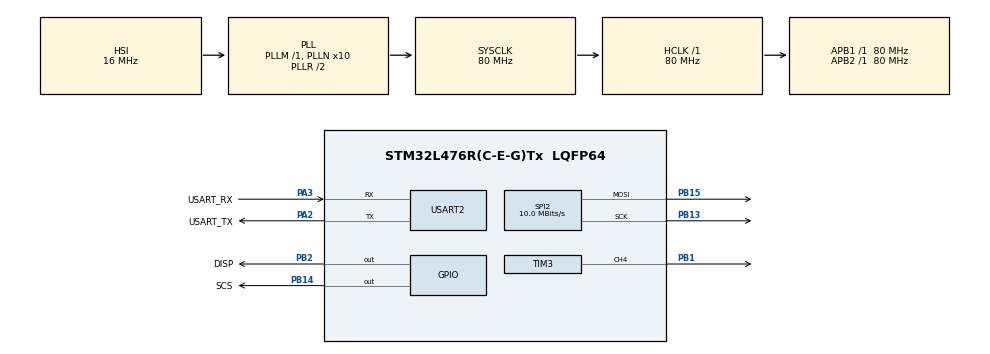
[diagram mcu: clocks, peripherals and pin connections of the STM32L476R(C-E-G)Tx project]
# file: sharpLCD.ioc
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Mcu.Family=STM32L4
Mcu.Name=STM32L476R(C-E-G)Tx
Mcu.Package=LQFP64
NVIC.PriorityGroup=NVIC_PRIORITYGROUP_4
PA13\ (JTMS-SWDIO).Mode=Serial_Wire
PA13\ (JTMS-SWDIO).Signal=SYS_JTMS-SWDIO
PA14\ (JTCK-SWCLK).Mode=Serial_Wire
PA14\ (JTCK-SWCLK).Signal=SYS_JTCK-SWCLK
PA2.GPIO_Label=USART_TX
PA2.GPIO_Mode=GPIO_MODE_AF_PP
PA2.GPIO_ModeDefaultPP=GPIO_MODE_AF_PP
PA2.GPIO_PuPd=GPIO_NOPULL
PA2.GPIO_Speed=GPIO_SPEED_FREQ_VERY_HIGH
PA2.Mode=Asynchronous
PA2.Signal=USART2_TX
PA3.GPIO_Label=USART_RX
PA3.GPIO_Mode=GPIO_MODE_AF_PP
PA3.GPIO_ModeDefaultPP=GPIO_MODE_AF_PP
PA3.GPIO_PuPd=GPIO_NOPULL
PA3.GPIO_Speed=GPIO_SPEED_FREQ_VERY_HIGH
PA3.Mode=Asynchronous
PA3.Signal=USART2_RX
PB1.Signal=S_TIM3_CH4
PB13.GPIO_Mode=GPIO_MODE_AF_PP
PB13.GPIO_PuPd=GPIO_NOPULL
PB13.GPIO_Speed=GPIO_SPEED_FREQ_VERY_HIGH
PB13.Mode=TX_Only_Simplex_Unidirect_Master
PB13.Signal=SPI2_SCK
PB14.GPIO_Label=SCS
PB14.GPIO_Speed=GPIO_SPEED_FREQ_VERY_HIGH
PB14.Signal=GPIO_Output
PB15.GPIO_Mode=GPIO_MODE_AF_PP
PB15.GPIO_PuPd=GPIO_NOPULL
PB15.GPIO_Speed=GPIO_SPEED_FREQ_VERY_HIGH
PB15.Mode=TX_Only_Simplex_Unidirect_Master
PB15.Signal=SPI2_MOSI
PB2.GPIO_Label=DISP
PB2.Signal=GPIO_Output
PB3\ (JTDO-TRACESWO).Signal=SYS_JTDO-SWO
PC15-OSC32_OUT\ (PC15).Signal=RCC_OSC32_OUT
PH0-OSC_IN\ (PH0).Signal=RCC_OSC_IN
PH1-OSC_OUT\ (PH1).Signal=RCC_OSC_OUT
ProjectManager.HeapSize=0x200
ProjectManager.StackSize=0x400
ProjectManager.TargetToolchain=MDK-ARM V5.27
RCC.ADCFreq_Value=96000000
RCC.AHBFreq_Value=80000000
RCC.APB1Freq_Value=80000000
RCC.APB1TimFreq_Value=80000000
RCC.APB2Freq_Value=80000000
RCC.APB2TimFreq_Value=80000000
RCC.CortexFreq_Value=80000000
RCC.HCLKFreq_Value=80000000
RCC.HSE_VALUE=8000000
RCC.HSI_VALUE=16000000
RCC.LSE_VALUE=32768
RCC.MSI_VALUE=4000000
RCC.PLLN=10
RCC.PLLSAI1N=12
RCC.PLLSourceVirtual=RCC_PLLSOURCE_HSI
RCC.PREFETCH_ENABLE=1
RCC.SYSCLKFreq_VALUE=80000000
RCC.SYSCLKSource=RCC_SYSCLKSOURCE_PLLCLK
RCC.USBFreq_Value=96000000
RCC.VCOOutputFreq_Value=160000000
SH.S_TIM3_CH4.0=TIM3_CH4,PWM Generation4 CH4
SPI2.BaudRatePrescaler=SPI_BAUDRATEPRESCALER_8
SPI2.CalculateBaudRate=10.0 MBits/s
SPI2.DataSize=SPI_DATASIZE_8BIT
SPI2.Direction=SPI_DIRECTION_2LINES
SPI2.FirstBit=SPI_FIRSTBIT_LSB
SPI2.Mode=SPI_MODE_MASTER
SPI2.VirtualType=VM_MASTER
TIM3.Channel-PWM\ Generation4\ CH4=TIM_CHANNEL_4
TIM3.Period=199
TIM3.Prescaler=9999
TIM3.Pulse-PWM\ Generation4\ CH4=100
USART2.VirtualMode-Asynchronous=VM_ASYNC
VP_TIM3_VS_ClockSourceINT.Mode=Internal
board=NUCLEO-L476RG

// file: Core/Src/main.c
/* USER CODE BEGIN Header */
/**
  ******************************************************************************
  * @file           : main.c
  * @brief          : Main program body
  ******************************************************************************
  * @attention
  *
  * <h2><center>&copy; Copyright (c) 2020 STMicroelectronics.
  * All rights reserved.</center></h2>
  *
  * This software component is licensed by ST under BSD 3-Clause license,
  * the "License"; You may not use this file except in compliance with the
  * License. You may obtain a copy of the License at:
  *                        opensource.org/licenses/BSD-3-Clause
  *
  ******************************************************************************
  */
/* USER CODE END Header */
#include "main.h"

/* USER CODE BEGIN PTD */
static uint8_t LCD_CMD_CLEAR = 0x56; // 0b01010110
static uint8_t LCD_CMD_UPDATE = 0x93; // 0b10010011
static uint8_t LCD_CMD_NOP = 0x00;
/* USER CODE END PTD */

SPI_HandleTypeDef hspi2;

TIM_HandleTypeDef htim3;

UART_HandleTypeDef huart2;

void SystemClock_Config(void);
static void MX_GPIO_Init(void);
static void MX_TIM3_Init(void);
static void MX_USART2_UART_Init(void);
static void MX_SPI2_Init(void);
/* USER CODE BEGIN PFP */
uint8_t LCD_BUFF[240][50] = {
0 , 0 , 0 , 168 , 170 , 170 , 170 , 170 , 170 , 42 , 34 , 186 , 170 , 170 , 170 , 170 , 254 , 255 , 254 , 255 , 254 , 255 , 238 , 238 , 238 , 174 , 174 , 234 , 238 , 238 , 170 , 34 , 162 , 34 , 2 , 42 , 0 , 0 , 0 , 32 , 0 , 0 , 32 , 0 , 0 , 0 , 0 , 0 , 0 , 0 ,
0 , 0 , 0 , 84 , 85 , 68 , 68 , 68 , 0 , 0 , 0 , 80 , 68 , 0 , 0 , 64 , 213 , 127 , 85 , 125 , 93 , 127 , 85 , 85 , 85 , 85 , 69 , 84 , 85 , 85 , 85 , 5 , 0 , 0 , 0 , 0 , 0 , 0 , 0 , 0 , 0 , 0 , 0 , 0 , 0 , 0 , 0 , 0 , 0 , 0 ,
0 , 0 , 0 , 168 , 170 , 170 , 170 , 170 , 170 , 138 , 0 , 184 , 170 , 170 , 170 , 170 , 251 , 191 , 191 , 187 , 191 , 191 , 171 , 170 , 186 , 171 , 170 , 186 , 187 , 171 , 170 , 138 , 136 , 8 , 0 , 40 , 0 , 0 , 0 , 0 , 0 , 0 , 0 , 0 , 0 , 0 , 0 , 0 , 0 , 0 ,
0 , 0 , 0 , 84 , 17 , 17 , 17 , 0 , 0 , 0 , 0 , 92 , 1 , 0 , 0 , 85 , 213 , 95 , 85 , 93 , 213 , 85 , 85 , 85 , 85 , 85 , 85 , 85 , 85 , 85 , 85 , 1 , 0 , 0 , 0 , 0 , 0 , 0 , 0 , 0 , 0 , 0 , 0 , 0 , 0 , 0 , 0 , 0 , 0 , 0 ,
0 , 0 , 0 , 168 , 170 , 170 , 170 , 170 , 170 , 170 , 162 , 174 , 170 , 170 , 170 , 254 , 238 , 255 , 238 , 254 , 239 , 239 , 238 , 238 , 238 , 238 , 234 , 234 , 250 , 174 , 170 , 170 , 34 , 170 , 2 , 160 , 0 , 0 , 0 , 32 , 0 , 0 , 32 , 0 , 0 , 0 , 0 , 0 , 0 , 0 ,
0 , 0 , 0 , 84 , 85 , 68 , 68 , 68 , 4 , 0 , 0 , 84 , 5 , 0 , 84 , 85 , 213 , 95 , 85 , 93 , 215 , 85 , 85 , 85 , 85 , 85 , 69 , 69 , 80 , 85 , 85 , 5 , 0 , 0 , 0 , 0 , 0 , 0 , 0 , 0 , 0 , 0 , 0 , 0 , 0 , 0 , 0 , 0 , 0 , 0 ,
0 , 0 , 0 , 168 , 170 , 170 , 170 , 170 , 170 , 170 , 136 , 170 , 170 , 170 , 170 , 171 , 250 , 191 , 186 , 190 , 251 , 171 , 170 , 170 , 170 , 171 , 170 , 171 , 186 , 170 , 170 , 170 , 136 , 136 , 10 , 128 , 0 , 0 , 0 , 8 , 0 , 0 , 0 , 0 , 0 , 0 , 0 , 0 , 0 , 0 ,
0 , 0 , 0 , 80 , 17 , 17 , 17 , 0 , 0 , 0 , 0 , 84 , 1 , 16 , 85 , 85 , 213 , 95 , 85 , 85 , 213 , 85 , 85 , 85 , 85 , 85 , 81 , 85 , 85 , 85 , 85 , 17 , 0 , 0 , 0 , 0 , 0 , 0 , 0 , 0 , 0 , 0 , 0 , 0 , 0 , 0 , 0 , 0 , 0 , 0 ,
0 , 0 , 0 , 168 , 170 , 170 , 170 , 170 , 170 , 170 , 170 , 174 , 170 , 170 , 175 , 170 , 238 , 255 , 255 , 255 , 255 , 239 , 238 , 238 , 238 , 238 , 234 , 238 , 238 , 170 , 170 , 170 , 162 , 170 , 42 , 0 , 34 , 0 , 0 , 2 , 0 , 32 , 0 , 0 , 0 , 0 , 0 , 0 , 0 , 0 ,
0 , 0 , 0 , 84 , 85 , 68 , 68 , 68 , 68 , 64 , 68 , 85 , 85 , 85 , 85 , 85 , 245 , 127 , 119 , 247 , 119 , 85 , 85 , 85 , 85 , 85 , 85 , 85 , 84 , 85 , 85 , 85 , 0 , 64 , 4 , 0 , 0 , 0 , 0 , 0 , 0 , 0 , 0 , 0 , 0 , 0 , 0 , 0 , 0 , 0 ,
0 , 0 , 0 , 168 , 170 , 170 , 170 , 170 , 170 , 170 , 170 , 175 , 170 , 186 , 170 , 170 , 250 , 255 , 255 , 255 , 255 , 191 , 170 , 170 , 170 , 170 , 170 , 187 , 186 , 170 , 170 , 170 , 136 , 170 , 170 , 0 , 0 , 8 , 0 , 0 , 0 , 0 , 0 , 0 , 0 , 0 , 0 , 0 , 0 , 0 ,
0 , 0 , 0 , 20 , 17 , 17 , 17 , 1 , 0 , 0 , 81 , 85 , 85 , 85 , 85 , 85 , 245 , 223 , 85 , 215 , 93 , 221 , 85 , 85 , 85 , 85 , 85 , 21 , 85 , 85 , 85 , 21 , 1 , 0 , 17 , 1 , 0 , 0 , 0 , 0 , 0 , 0 , 0 , 0 , 0 , 0 , 0 , 0 , 0 , 0 ,
0 , 0 , 0 , 168 , 170 , 170 , 170 , 170 , 170 , 170 , 234 , 239 , 238 , 170 , 170 , 234 , 251 , 255 , 255 , 239 , 255 , 255 , 239 , 238 , 238 , 238 , 238 , 174 , 238 , 170 , 170 , 170 , 170 , 170 , 170 , 10 , 32 , 42 , 32 , 0 , 160 , 2 , 0 , 0 , 0 , 0 , 0 , 0 , 0 , 0 ,
0 , 0 , 0 , 84 , 85 , 68 , 68 , 68 , 68 , 84 , 85 , 85 , 85 , 85 , 85 , 85 , 247 , 127 , 119 , 215 , 117 , 119 , 85 , 85 , 85 , 85 , 85 , 69 , 85 , 85 , 85 , 85 , 5 , 68 , 85 , 5 , 0 , 0 , 0 , 0 , 0 , 0 , 0 , 0 , 0 , 0 , 0 , 0 , 0 , 0 ,
0 , 0 , 0 , 168 , 170 , 170 , 170 , 170 , 170 , 170 , 250 , 187 , 170 , 170 , 170 , 187 , 251 , 255 , 255 , 255 , 255 , 255 , 251 , 171 , 170 , 170 , 170 , 170 , 187 , 170 , 170 , 170 , 138 , 170 , 170 , 10 , 0 , 136 , 8 , 0 , 128 , 0 , 0 , 0 , 0 , 0 , 0 , 0 , 0 , 0 ,
0 , 0 , 0 , 84 , 17 , 17 , 17 , 1 , 16 , 85 , 85 , 85 , 85 , 85 , 81 , 125 , 221 , 93 , 85 , 215 , 85 , 85 , 213 , 85 , 85 , 85 , 85 , 17 , 85 , 85 , 85 , 85 , 17 , 16 , 17 , 1 , 0 , 0 , 0 , 0 , 0 , 0 , 0 , 0 , 0 , 0 , 0 , 0 , 0 , 0 ,
0 , 0 , 0 , 168 , 170 , 170 , 170 , 170 , 170 , 238 , 239 , 238 , 174 , 170 , 234 , 255 , 255 , 255 , 255 , 255 , 255 , 254 , 255 , 239 , 238 , 238 , 238 , 170 , 238 , 170 , 170 , 170 , 42 , 170 , 170 , 42 , 0 , 2 , 42 , 2 , 40 , 0 , 32 , 0 , 0 , 0 , 0 , 0 , 0 , 0 ,
0 , 0 , 0 , 84 , 85 , 68 , 68 , 68 , 84 , 85 , 85 , 85 , 85 , 85 , 117 , 255 , 255 , 119 , 119 , 87 , 117 , 87 , 85 , 87 , 85 , 85 , 85 , 5 , 84 , 85 , 85 , 85 , 85 , 84 , 85 , 5 , 0 , 0 , 0 , 0 , 0 , 0 , 0 , 0 , 0 , 0 , 0 , 0 , 0 , 0 ,
0 , 0 , 0 , 168 , 170 , 170 , 170 , 170 , 170 , 187 , 187 , 171 , 170 , 170 , 255 , 255 , 255 , 255 , 255 , 191 , 255 , 187 , 187 , 191 , 171 , 170 , 186 , 138 , 186 , 170 , 170 , 170 , 170 , 170 , 170 , 42 , 0 , 0 , 8 , 128 , 10 , 0 , 0 , 0 , 0 , 0 , 0 , 0 , 0 , 0 ,
0 , 0 , 0 , 84 , 21 , 17 , 17 , 16 , 85 , 85 , 85 , 85 , 85 , 213 , 223 , 255 , 221 , 93 , 85 , 213 , 85 , 85 , 85 , 85 , 85 , 85 , 85 , 69 , 85 , 85 , 85 , 85 , 21 , 17 , 17 , 17 , 0 , 0 , 0 , 0 , 0 , 0 , 0 , 0 , 0 , 0 , 0 , 0 , 0 , 0 ,
0 , 0 , 0 , 168 , 170 , 170 , 170 , 234 , 254 , 238 , 255 , 239 , 255 , 255 , 239 , 255 , 255 , 255 , 255 , 255 , 255 , 239 , 238 , 238 , 239 , 238 , 238 , 174 , 239 , 170 , 170 , 174 , 170 , 170 , 170 , 170 , 40 , 32 , 170 , 170 , 34 , 0 , 32 , 32 , 32 , 0 , 0 , 0 , 0 , 0 ,
0 , 0 , 0 , 84 , 85 , 69 , 68 , 85 , 85 , 85 , 85 , 117 , 119 , 87 , 117 , 85 , 127 , 127 , 119 , 87 , 117 , 87 , 85 , 85 , 87 , 85 , 85 , 85 , 85 , 85 , 85 , 85 , 85 , 85 , 85 , 69 , 80 , 0 , 68 , 68 , 0 , 0 , 0 , 0 , 0 , 0 , 0 , 0 , 0 , 0 ,
0 , 0 , 0 , 168 , 170 , 170 , 170 , 186 , 187 , 170 , 170 , 170 , 170 , 170 , 186 , 170 , 255 , 255 , 255 , 191 , 255 , 191 , 187 , 187 , 191 , 187 , 171 , 187 , 171 , 170 , 170 , 170 , 170 , 170 , 170 , 170 , 186 , 138 , 170 , 170 , 170 , 8 , 0 , 0 , 0 , 0 , 0 , 0 , 0 , 0 ,
0 , 0 , 0 , 84 , 85 , 17 , 85 , 85 , 85 , 85 , 21 , 17 , 17 , 85 , 85 , 213 , 223 , 93 , 85 , 85 , 85 , 85 , 85 , 85 , 85 , 85 , 85 , 85 , 85 , 85 , 85 , 85 , 21 , 17 , 17 , 17 , 81 , 1 , 0 , 1 , 0 , 0 , 0 , 0 , 0 , 0 , 0 , 0 , 0 , 0 ,
0 , 0 , 0 , 236 , 170 , 234 , 254 , 239 , 238 , 170 , 170 , 170 , 170 , 170 , 170 , 238 , 255 , 255 , 255 , 239 , 255 , 239 , 238 , 238 , 254 , 238 , 238 , 238 , 174 , 170 , 170 , 170 , 170 , 170 , 170 , 170 , 234 , 170 , 170 , 170 , 170 , 42 , 42 , 162 , 2 , 34 , 0 , 0 , 0 , 0 ,
0 , 0 , 0 , 84 , 85 , 85 , 245 , 85 , 85 , 85 , 85 , 85 , 85 , 85 , 85 , 213 , 127 , 127 , 127 , 95 , 117 , 87 , 85 , 85 , 85 , 85 , 85 , 85 , 85 , 85 , 85 , 85 , 85 , 85 , 85 , 69 , 84 , 69 , 4 , 0 , 0 , 0 , 0 , 0 , 4 , 0 , 0 , 0 , 0 , 0 ,
0 , 0 , 0 , 184 , 187 , 251 , 255 , 187 , 171 , 170 , 170 , 170 , 170 , 170 , 170 , 234 , 255 , 255 , 255 , 255 , 255 , 191 , 170 , 187 , 187 , 187 , 171 , 187 , 187 , 170 , 170 , 170 , 170 , 170 , 170 , 170 , 170 , 170 , 170 , 138 , 136 , 170 , 128 , 128 , 136 , 0 , 0 , 0 , 0 , 0 ,
0 , 0 , 0 , 84 , 85 , 21 , 212 , 85 , 85 , 21 , 17 , 17 , 81 , 17 , 17 , 213 , 221 , 93 , 85 , 221 , 221 , 85 , 85 , 85 , 85 , 85 , 85 , 85 , 85 , 85 , 85 , 85 , 85 , 17 , 17 , 17 , 81 , 1 , 0 , 0 , 0 , 0 , 0 , 0 , 0 , 0 , 0 , 0 , 0 , 0 ,
0 , 0 , 0 , 252 , 238 , 42 , 254 , 239 , 174 , 170 , 170 , 170 , 170 , 170 , 170 , 234 , 255 , 255 , 255 , 255 , 255 , 255 , 238 , 238 , 254 , 254 , 238 , 239 , 238 , 170 , 170 , 170 , 170 , 170 , 170 , 170 , 234 , 170 , 170 , 42 , 0 , 34 , 42 , 34 , 32 , 0 , 0 , 0 , 0 , 0 ,
0 , 0 , 0 , 124 , 85 , 21 , 116 , 85 , 85 , 85 , 85 , 85 , 85 , 85 , 85 , 213 , 93 , 127 , 119 , 119 , 95 , 119 , 85 , 85 , 85 , 85 , 85 , 85 , 85 , 85 , 85 , 85 , 85 , 85 , 85 , 84 , 85 , 69 , 0 , 0 , 0 , 0 , 0 , 0 , 0 , 0 , 0 , 0 , 0 , 0 ,
0 , 0 , 0 , 188 , 170 , 43 , 254 , 187 , 171 , 170 , 170 , 170 , 170 , 170 , 170 , 186 , 255 , 255 , 255 , 255 , 255 , 255 , 187 , 170 , 186 , 187 , 187 , 187 , 187 , 171 , 170 , 170 , 170 , 170 , 170 , 170 , 186 , 170 , 168 , 8 , 0 , 0 , 0 , 0 , 128 , 0 , 0 , 0 , 0 , 0 ,
0 , 0 , 0 , 92 , 85 , 21 , 212 , 21 , 85 , 17 , 17 , 17 , 21 , 17 , 17 , 209 , 221 , 221 , 85 , 117 , 221 , 85 , 85 , 85 , 80 , 85 , 85 , 85 , 85 , 85 , 85 , 85 , 85 , 21 , 17 , 81 , 85 , 17 , 0 , 0 , 0 , 0 , 0 , 0 , 0 , 0 , 0 , 0 , 0 , 0 ,
0 , 0 , 0 , 252 , 239 , 170 , 254 , 175 , 174 , 170 , 170 , 170 , 170 , 170 , 170 , 234 , 255 , 255 , 255 , 255 , 255 , 255 , 255 , 47 , 234 , 238 , 239 , 239 , 238 , 238 , 170 , 170 , 170 , 170 , 170 , 234 , 238 , 170 , 170 , 10 , 0 , 0 , 32 , 0 , 0 , 2 , 0 , 0 , 0 , 0 ,
0 , 0 , 0 , 84 , 71 , 85 , 116 , 85 , 85 , 85 , 85 , 85 , 85 , 85 , 85 , 212 , 119 , 247 , 119 , 247 , 255 , 119 , 119 , 7 , 80 , 85 , 85 , 85 , 85 , 85 , 85 , 85 , 85 , 85 , 85 , 68 , 85 , 69 , 4 , 4 , 0 , 0 , 0 , 0 , 0 , 0 , 0 , 0 , 0 , 0 ,
0 , 0 , 0 , 236 , 175 , 171 , 248 , 187 , 170 , 170 , 170 , 170 , 170 , 170 , 234 , 251 , 191 , 255 , 255 , 255 , 255 , 255 , 255 , 175 , 170 , 186 , 171 , 187 , 187 , 187 , 171 , 170 , 170 , 170 , 170 , 170 , 170 , 170 , 138 , 10 , 0 , 0 , 128 , 0 , 0 , 0 , 0 , 0 , 0 , 0 ,
0 , 0 , 0 , 212 , 85 , 21 , 84 , 85 , 21 , 17 , 17 , 17 , 17 , 17 , 1 , 209 , 93 , 221 , 95 , 213 , 93 , 93 , 85 , 85 , 4 , 85 , 85 , 85 , 85 , 85 , 85 , 85 , 85 , 21 , 17 , 81 , 85 , 17 , 5 , 0 , 0 , 0 , 0 , 0 , 0 , 0 , 0 , 0 , 0 , 0 ,
0 , 0 , 0 , 252 , 63 , 174 , 250 , 191 , 170 , 170 , 170 , 170 , 170 , 170 , 170 , 238 , 255 , 255 , 255 , 255 , 255 , 255 , 255 , 255 , 170 , 238 , 254 , 238 , 238 , 238 , 238 , 170 , 170 , 170 , 170 , 234 , 238 , 170 , 42 , 34 , 0 , 0 , 0 , 2 , 0 , 32 , 0 , 0 , 0 , 0 ,
0 , 0 , 0 , 244 , 23 , 84 , 116 , 85 , 85 , 85 , 85 , 85 , 85 , 69 , 68 , 92 , 119 , 255 , 127 , 117 , 247 , 119 , 87 , 85 , 69 , 85 , 85 , 85 , 85 , 85 , 85 , 85 , 85 , 85 , 85 , 85 , 85 , 85 , 20 , 0 , 0 , 0 , 0 , 0 , 0 , 0 , 0 , 0 , 0 , 0 ,
0 , 0 , 0 , 252 , 63 , 168 , 250 , 187 , 170 , 170 , 170 , 170 , 170 , 170 , 170 , 250 , 255 , 255 , 255 , 251 , 255 , 255 , 255 , 251 , 171 , 170 , 187 , 171 , 170 , 187 , 171 , 170 , 170 , 170 , 170 , 170 , 187 , 171 , 42 , 0 , 0 , 0 , 0 , 8 , 0 , 0 , 0 , 0 , 0 , 0 ,
0 , 0 , 0 , 212 , 29 , 16 , 81 , 85 , 21 , 17 , 17 , 17 , 17 , 21 , 17 , 80 , 213 , 221 , 125 , 85 , 223 , 93 , 85 , 85 , 21 , 81 , 85 , 21 , 85 , 85 , 85 , 17 , 85 , 85 , 17 , 81 , 85 , 85 , 17 , 0 , 0 , 0 , 0 , 0 , 0 , 0 , 0 , 0 , 0 , 0 ,
0 , 0 , 0 , 252 , 63 , 184 , 250 , 239 , 170 , 170 , 170 , 170 , 170 , 170 , 170 , 234 , 255 , 255 , 255 , 239 , 255 , 255 , 254 , 255 , 238 , 234 , 238 , 238 , 234 , 238 , 238 , 170 , 170 , 170 , 170 , 234 , 238 , 238 , 170 , 2 , 0 , 0 , 0 , 32 , 0 , 0 , 0 , 0 , 0 , 0 ,
0 , 0 , 0 , 84 , 95 , 80 , 116 , 85 , 85 , 85 , 85 , 85 , 85 , 69 , 68 , 68 , 127 , 247 , 255 , 87 , 253 , 127 , 85 , 85 , 85 , 85 , 85 , 85 , 85 , 85 , 85 , 85 , 85 , 85 , 85 , 85 , 85 , 85 , 69 , 0 , 0 , 0 , 0 , 0 , 0 , 0 , 0 , 0 , 0 , 0 ,
0 , 0 , 0 , 184 , 63 , 160 , 186 , 187 , 171 , 170 , 170 , 170 , 170 , 170 , 170 , 234 , 255 , 255 , 255 , 191 , 251 , 255 , 255 , 187 , 187 , 171 , 186 , 255 , 171 , 170 , 186 , 170 , 170 , 170 , 170 , 186 , 171 , 187 , 170 , 10 , 0 , 0 , 0 , 128 , 0 , 0 , 0 , 0 , 0 , 0 ,
0 , 0 , 0 , 84 , 21 , 64 , 85 , 85 , 85 , 17 , 17 , 17 , 17 , 17 , 1 , 192 , 221 , 213 , 221 , 95 , 245 , 255 , 85 , 85 , 85 , 21 , 85 , 93 , 85 , 85 , 85 , 85 , 17 , 85 , 17 , 81 , 85 , 85 , 17 , 1 , 0 , 0 , 0 , 0 , 0 , 0 , 0 , 0 , 0 , 0 ,
0 , 0 , 0 , 252 , 42 , 224 , 250 , 190 , 171 , 170 , 170 , 170 , 170 , 170 , 170 , 170 , 255 , 255 , 255 , 255 , 255 , 255 , 255 , 255 , 255 , 191 , 234 , 254 , 175 , 238 , 238 , 238 , 170 , 170 , 170 , 234 , 238 , 238 , 170 , 42 , 2 , 0 , 0 , 0 , 2 , 0 , 0 , 0 , 0 , 0 ,
0 , 0 , 0 , 84 , 85 , 64 , 85 , 85 , 85 , 85 , 85 , 85 , 85 , 69 , 68 , 64 , 119 , 119 , 247 , 127 , 245 , 255 , 87 , 85 , 85 , 85 , 84 , 85 , 85 , 85 , 85 , 85 , 85 , 85 , 85 , 85 , 85 , 85 , 69 , 1 , 0 , 0 , 0 , 0 , 0 , 0 , 0 , 0 , 0 , 0 ,
0 , 0 , 0 , 168 , 42 , 128 , 186 , 251 , 171 , 170 , 170 , 170 , 170 , 170 , 170 , 170 , 254 , 255 , 255 , 255 , 255 , 255 , 239 , 187 , 187 , 187 , 170 , 254 , 187 , 170 , 170 , 170 , 171 , 170 , 170 , 186 , 171 , 186 , 171 , 2 , 0 , 0 , 0 , 0 , 0 , 0 , 0 , 0 , 0 , 0 ,
0 , 0 , 0 , 84 , 21 , 0 , 85 , 85 , 21 , 17 , 17 , 17 , 21 , 17 , 1 , 0 , 221 , 93 , 221 , 253 , 215 , 221 , 95 , 85 , 85 , 85 , 81 , 85 , 21 , 85 , 85 , 85 , 21 , 81 , 21 , 85 , 85 , 85 , 21 , 1 , 0 , 0 , 0 , 0 , 0 , 0 , 0 , 0 , 0 , 0 ,
0 , 0 , 0 , 172 , 42 , 130 , 254 , 238 , 175 , 170 , 170 , 170 , 170 , 170 , 170 , 170 , 254 , 255 , 255 , 255 , 255 , 255 , 255 , 255 , 255 , 255 , 170 , 254 , 191 , 238 , 238 , 238 , 174 , 170 , 170 , 238 , 238 , 238 , 174 , 42 , 2 , 0 , 0 , 0 , 34 , 0 , 0 , 0 , 0 , 0 ,
0 , 0 , 0 , 84 , 85 , 0 , 85 , 85 , 85 , 85 , 85 , 85 , 85 , 69 , 68 , 64 , 244 , 247 , 119 , 255 , 127 , 255 , 127 , 85 , 85 , 85 , 69 , 85 , 85 , 85 , 85 , 85 , 85 , 85 , 85 , 85 , 85 , 85 , 85 , 68 , 0 , 0 , 0 , 0 , 0 , 0 , 0 , 0 , 0 , 0 ,
0 , 0 , 0 , 168 , 42 , 128 , 191 , 187 , 171 , 170 , 170 , 170 , 170 , 170 , 170 , 170 , 250 , 255 , 255 , 255 , 255 , 255 , 255 , 190 , 187 , 187 , 171 , 254 , 187 , 170 , 171 , 170 , 186 , 171 , 170 , 186 , 187 , 171 , 171 , 170 , 0 , 0 , 0 , 0 , 0 , 0 , 0 , 0 , 0 , 0 ,
0 , 0 , 0 , 84 , 21 , 0 , 93 , 85 , 85 , 17 , 81 , 21 , 17 , 21 , 1 , 0 , 208 , 223 , 221 , 221 , 253 , 221 , 221 , 85 , 85 , 85 , 21 , 85 , 85 , 84 , 85 , 85 , 85 , 21 , 17 , 81 , 85 , 85 , 21 , 1 , 1 , 0 , 0 , 0 , 0 , 0 , 0 , 0 , 0 , 0 ,
0 , 0 , 0 , 172 , 42 , 160 , 255 , 238 , 175 , 170 , 234 , 170 , 170 , 170 , 170 , 170 , 234 , 255 , 255 , 255 , 255 , 255 , 255 , 255 , 255 , 255 , 175 , 254 , 255 , 234 , 238 , 238 , 238 , 174 , 170 , 234 , 238 , 238 , 174 , 170 , 2 , 0 , 0 , 0 , 0 , 0 , 0 , 0 , 0 , 0 ,
0 , 0 , 0 , 84 , 85 , 0 , 95 , 85 , 85 , 85 , 69 , 85 , 85 , 69 , 69 , 64 , 68 , 255 , 255 , 255 , 255 , 255 , 119 , 87 , 85 , 85 , 69 , 117 , 85 , 65 , 85 , 85 , 85 , 85 , 85 , 85 , 85 , 85 , 85 , 20 , 4 , 0 , 0 , 0 , 0 , 0 , 0 , 0 , 0 , 0 ,
0 , 0 , 0 , 168 , 42 , 0 , 254 , 171 , 171 , 170 , 170 , 170 , 170 , 170 , 170 , 170 , 170 , 254 , 255 , 255 , 255 , 255 , 255 , 239 , 187 , 187 , 171 , 250 , 191 , 171 , 187 , 171 , 170 , 186 , 170 , 186 , 187 , 187 , 187 , 42 , 10 , 0 , 0 , 0 , 0 , 0 , 0 , 0 , 0 , 0 ,
0 , 0 , 0 , 80 , 21 , 0 , 92 , 85 , 85 , 21 , 17 , 17 , 17 , 17 , 1 , 1 , 1 , 252 , 253 , 221 , 221 , 221 , 221 , 85 , 85 , 85 , 21 , 81 , 85 , 5 , 85 , 85 , 85 , 85 , 17 , 81 , 85 , 85 , 85 , 17 , 0 , 0 , 0 , 0 , 0 , 0 , 0 , 0 , 0 , 0 ,
0 , 0 , 0 , 168 , 42 , 32 , 254 , 174 , 175 , 170 , 170 , 170 , 170 , 170 , 170 , 170 , 170 , 250 , 255 , 255 , 255 , 255 , 255 , 191 , 255 , 255 , 175 , 250 , 239 , 42 , 234 , 238 , 238 , 238 , 170 , 234 , 238 , 238 , 238 , 170 , 168 , 2 , 0 , 0 , 0 , 0 , 0 , 0 , 0 , 0 ,
0 , 0 , 0 , 84 , 85 , 0 , 116 , 85 , 85 , 85 , 85 , 84 , 85 , 85 , 69 , 64 , 68 , 212 , 255 , 247 , 255 , 255 , 119 , 87 , 87 , 85 , 85 , 84 , 85 , 85 , 84 , 85 , 85 , 85 , 85 , 85 , 85 , 85 , 85 , 69 , 64 , 0 , 0 , 0 , 0 , 0 , 0 , 0 , 0 , 0 ,
0 , 0 , 0 , 168 , 170 , 0 , 248 , 139 , 187 , 170 , 170 , 170 , 170 , 170 , 170 , 138 , 170 , 170 , 255 , 255 , 255 , 255 , 255 , 191 , 190 , 187 , 171 , 250 , 171 , 170 , 170 , 186 , 170 , 170 , 170 , 186 , 187 , 187 , 187 , 170 , 128 , 10 , 0 , 0 , 0 , 0 , 0 , 0 , 0 , 0 ,
0 , 0 , 0 , 80 , 85 , 0 , 80 , 21 , 85 , 21 , 17 , 17 , 17 , 17 , 17 , 17 , 0 , 80 , 253 , 223 , 221 , 221 , 93 , 93 , 85 , 85 , 21 , 81 , 85 , 21 , 1 , 80 , 85 , 85 , 85 , 85 , 85 , 85 , 85 , 1 , 0 , 0 , 0 , 0 , 0 , 0 , 0 , 0 , 0 , 0 ,
0 , 0 , 0 , 168 , 170 , 34 , 224 , 175 , 250 , 170 , 170 , 170 , 170 , 170 , 170 , 170 , 170 , 234 , 254 , 255 , 255 , 255 , 255 , 255 , 251 , 255 , 175 , 234 , 170 , 170 , 170 , 234 , 238 , 238 , 170 , 254 , 238 , 238 , 238 , 170 , 42 , 162 , 2 , 0 , 0 , 0 , 0 , 0 , 0 , 0 ,
0 , 0 , 0 , 84 , 85 , 0 , 96 , 85 , 85 , 85 , 85 , 69 , 85 , 85 , 85 , 85 , 85 , 68 , 245 , 255 , 255 , 127 , 127 , 119 , 119 , 85 , 85 , 84 , 85 , 85 , 69 , 65 , 85 , 85 , 85 , 85 , 85 , 85 , 85 , 69 , 0 , 0 , 4 , 0 , 0 , 0 , 0 , 0 , 0 , 0 ,
0 , 0 , 0 , 168 , 170 , 0 , 224 , 171 , 186 , 170 , 170 , 170 , 170 , 170 , 170 , 170 , 170 , 170 , 186 , 255 , 255 , 255 , 255 , 251 , 239 , 187 , 171 , 170 , 170 , 170 , 170 , 170 , 170 , 170 , 170 , 250 , 187 , 187 , 187 , 170 , 0 , 128 , 10 , 0 , 0 , 0 , 0 , 0 , 0 , 0 ,
0 , 0 , 0 , 80 , 21 , 0 , 64 , 85 , 85 , 85 , 21 , 17 , 81 , 21 , 81 , 85 , 85 , 85 , 85 , 125 , 255 , 221 , 221 , 213 , 93 , 85 , 21 , 81 , 85 , 21 , 1 , 16 , 85 , 85 , 85 , 85 , 85 , 85 , 85 , 21 , 0 , 0 , 0 , 0 , 0 , 0 , 0 , 0 , 0 , 0 ,
0 , 0 , 0 , 168 , 42 , 34 , 226 , 239 , 238 , 170 , 170 , 170 , 170 , 170 , 170 , 170 , 238 , 238 , 238 , 255 , 254 , 255 , 255 , 239 , 255 , 255 , 191 , 170 , 170 , 170 , 42 , 186 , 238 , 234 , 238 , 254 , 255 , 238 , 238 , 174 , 42 , 32 , 42 , 32 , 2 , 32 , 0 , 0 , 0 , 0 ,
0 , 0 , 0 , 84 , 21 , 0 , 0 , 85 , 85 , 85 , 85 , 85 , 85 , 85 , 85 , 85 , 85 , 85 , 85 , 119 , 253 , 127 , 119 , 87 , 119 , 85 , 85 , 68 , 85 , 85 , 4 , 84 , 84 , 85 , 85 , 85 , 85 , 85 , 85 , 85 , 0 , 0 , 0 , 0 , 0 , 0 , 0 , 0 , 0 , 0 ,
0 , 0 , 0 , 168 , 170 , 8 , 128 , 171 , 186 , 171 , 170 , 170 , 170 , 170 , 170 , 170 , 170 , 187 , 191 , 255 , 255 , 255 , 255 , 255 , 255 , 187 , 187 , 170 , 170 , 170 , 10 , 186 , 168 , 170 , 170 , 250 , 191 , 187 , 170 , 170 , 8 , 128 , 128 , 0 , 0 , 0 , 0 , 0 , 0 , 0 ,
0 , 0 , 0 , 80 , 21 , 0 , 0 , 85 , 85 , 85 , 85 , 21 , 85 , 21 , 85 , 85 , 85 , 85 , 213 , 93 , 85 , 221 , 85 , 221 , 95 , 85 , 85 , 65 , 21 , 17 , 0 , 85 , 81 , 85 , 85 , 85 , 85 , 85 , 85 , 21 , 1 , 0 , 0 , 0 , 0 , 0 , 0 , 0 , 0 , 0 ,
0 , 0 , 0 , 168 , 170 , 10 , 2 , 174 , 254 , 175 , 170 , 170 , 238 , 238 , 238 , 238 , 255 , 255 , 255 , 255 , 175 , 254 , 174 , 170 , 254 , 255 , 239 , 234 , 175 , 170 , 162 , 255 , 170 , 174 , 234 , 254 , 255 , 239 , 238 , 174 , 34 , 32 , 34 , 2 , 2 , 0 , 0 , 0 , 0 , 0 ,
0 , 0 , 0 , 84 , 85 , 0 , 0 , 84 , 85 , 85 , 85 , 85 , 85 , 85 , 85 , 85 , 85 , 85 , 85 , 85 , 4 , 80 , 0 , 0 , 64 , 119 , 85 , 69 , 85 , 0 , 64 , 85 , 5 , 85 , 85 , 85 , 85 , 85 , 85 , 85 , 0 , 0 , 0 , 0 , 0 , 0 , 0 , 0 , 0 , 0 ,
0 , 0 , 0 , 168 , 170 , 10 , 0 , 188 , 186 , 175 , 170 , 170 , 170 , 187 , 187 , 187 , 171 , 170 , 170 , 170 , 10 , 56 , 0 , 0 , 136 , 254 , 187 , 170 , 170 , 138 , 234 , 187 , 59 , 170 , 170 , 250 , 255 , 187 , 187 , 170 , 2 , 0 , 0 , 8 , 0 , 0 , 0 , 0 , 0 , 0 ,
0 , 0 , 0 , 80 , 21 , 0 , 0 , 80 , 85 , 85 , 85 , 85 , 85 , 85 , 85 , 21 , 0 , 16 , 17 , 1 , 4 , 16 , 0 , 0 , 0 , 208 , 85 , 1 , 0 , 0 , 85 , 85 , 85 , 64 , 85 , 85 , 85 , 85 , 85 , 21 , 0 , 0 , 0 , 0 , 0 , 0 , 0 , 0 , 0 , 0 ,
0 , 0 , 0 , 168 , 170 , 42 , 34 , 248 , 254 , 254 , 234 , 238 , 238 , 254 , 175 , 170 , 170 , 170 , 170 , 170 , 170 , 42 , 34 , 34 , 2 , 226 , 255 , 42 , 168 , 170 , 234 , 239 , 254 , 163 , 254 , 250 , 255 , 255 , 238 , 174 , 34 , 32 , 34 , 34 , 0 , 0 , 0 , 0 , 0 , 0 ,
0 , 0 , 0 , 84 , 85 , 1 , 0 , 112 , 85 , 85 , 85 , 85 , 85 , 85 , 69 , 68 , 68 , 68 , 68 , 4 , 4 , 20 , 0 , 0 , 0 , 64 , 85 , 69 , 64 , 85 , 85 , 85 , 85 , 21 , 84 , 85 , 85 , 85 , 85 , 85 , 0 , 0 , 0 , 0 , 0 , 0 , 0 , 0 , 0 , 0 ,
0 , 0 , 0 , 168 , 170 , 10 , 0 , 224 , 235 , 187 , 170 , 170 , 187 , 171 , 170 , 170 , 170 , 170 , 170 , 170 , 138 , 26 , 0 , 0 , 0 , 128 , 239 , 171 , 168 , 170 , 234 , 187 , 187 , 187 , 186 , 187 , 251 , 191 , 187 , 171 , 2 , 0 , 0 , 128 , 0 , 0 , 0 , 0 , 0 , 0 ,
0 , 0 , 0 , 80 , 85 , 1 , 0 , 64 , 85 , 85 , 85 , 85 , 85 , 17 , 17 , 17 , 17 , 17 , 17 , 0 , 20 , 20 , 0 , 0 , 0 , 128 , 21 , 5 , 0 , 17 , 81 , 85 , 85 , 85 , 85 , 85 , 85 , 85 , 85 , 21 , 0 , 0 , 0 , 0 , 0 , 0 , 0 , 0 , 0 , 0 ,
0 , 0 , 0 , 168 , 170 , 42 , 34 , 224 , 239 , 239 , 238 , 238 , 175 , 170 , 170 , 170 , 170 , 170 , 170 , 170 , 174 , 62 , 34 , 34 , 0 , 128 , 255 , 174 , 160 , 170 , 234 , 239 , 254 , 238 , 238 , 255 , 255 , 255 , 255 , 175 , 34 , 32 , 32 , 2 , 2 , 0 , 0 , 0 , 0 , 0 ,
0 , 0 , 0 , 84 , 85 , 1 , 0 , 64 , 85 , 87 , 85 , 85 , 85 , 85 , 85 , 68 , 68 , 68 , 68 , 68 , 84 , 21 , 0 , 0 , 0 , 0 , 127 , 21 , 0 , 84 , 84 , 85 , 85 , 85 , 85 , 85 , 85 , 85 , 85 , 85 , 4 , 0 , 0 , 0 , 0 , 0 , 0 , 0 , 0 , 0 ,
0 , 0 , 0 , 168 , 170 , 10 , 0 , 128 , 255 , 191 , 187 , 187 , 170 , 170 , 170 , 170 , 170 , 170 , 170 , 170 , 170 , 186 , 0 , 0 , 0 , 0 , 255 , 191 , 130 , 170 , 170 , 187 , 187 , 187 , 187 , 186 , 255 , 255 , 187 , 171 , 10 , 0 , 8 , 0 , 0 , 0 , 0 , 0 , 0 , 0 ,
0 , 0 , 0 , 80 , 85 , 1 , 0 , 0 , 85 , 85 , 85 , 85 , 21 , 85 , 17 , 17 , 17 , 17 , 17 , 17 , 20 , 81 , 0 , 0 , 0 , 0 , 223 , 93 , 1 , 16 , 81 , 85 , 21 , 16 , 80 , 85 , 85 , 85 , 85 , 21 , 0 , 0 , 0 , 0 , 0 , 0 , 0 , 0 , 0 , 0 ,
0 , 0 , 0 , 168 , 170 , 10 , 34 , 32 , 254 , 255 , 238 , 238 , 170 , 170 , 170 , 170 , 170 , 170 , 170 , 170 , 174 , 234 , 34 , 34 , 2 , 0 , 254 , 255 , 171 , 170 , 234 , 175 , 170 , 170 , 174 , 238 , 255 , 255 , 255 , 174 , 42 , 2 , 0 , 0 , 0 , 0 , 0 , 0 , 0 , 0 ,
0 , 0 , 0 , 84 , 85 , 5 , 0 , 0 , 84 , 117 , 85 , 85 , 85 , 69 , 85 , 69 , 69 , 68 , 69 , 68 , 68 , 84 , 1 , 0 , 0 , 0 , 254 , 119 , 95 , 84 , 85 , 87 , 85 , 85 , 85 , 117 , 85 , 85 , 85 , 85 , 4 , 0 , 0 , 0 , 0 , 0 , 0 , 0 , 0 , 0 ,
0 , 0 , 0 , 168 , 170 , 10 , 0 , 0 , 248 , 251 , 187 , 171 , 170 , 170 , 171 , 170 , 170 , 170 , 170 , 170 , 170 , 170 , 139 , 8 , 0 , 0 , 254 , 255 , 255 , 171 , 170 , 191 , 187 , 187 , 187 , 234 , 255 , 255 , 187 , 171 , 10 , 0 , 0 , 0 , 0 , 0 , 0 , 0 , 0 , 0 ,
0 , 0 , 0 , 80 , 85 , 1 , 0 , 0 , 64 , 85 , 85 , 85 , 85 , 21 , 17 , 17 , 17 , 17 , 17 , 17 , 21 , 17 , 5 , 0 , 0 , 0 , 252 , 95 , 213 , 21 , 85 , 85 , 85 , 85 , 85 , 209 , 85 , 85 , 85 , 21 , 0 , 0 , 0 , 0 , 0 , 0 , 0 , 0 , 0 , 0 ,
0 , 0 , 0 , 168 , 170 , 42 , 34 , 32 , 162 , 254 , 255 , 175 , 170 , 170 , 170 , 170 , 170 , 170 , 170 , 170 , 174 , 170 , 190 , 42 , 34 , 2 , 254 , 255 , 255 , 175 , 239 , 239 , 238 , 238 , 238 , 254 , 251 , 255 , 255 , 175 , 42 , 34 , 34 , 0 , 0 , 0 , 0 , 0 , 0 , 0 ,
0 , 0 , 0 , 84 , 85 , 5 , 0 , 0 , 0 , 84 , 85 , 85 , 85 , 85 , 84 , 85 , 85 , 85 , 85 , 85 , 85 , 85 , 117 , 0 , 0 , 0 , 255 , 127 , 119 , 85 , 87 , 87 , 85 , 85 , 85 , 21 , 71 , 85 , 85 , 85 , 0 , 0 , 0 , 0 , 0 , 0 , 0 , 0 , 0 , 0 ,
0 , 0 , 0 , 168 , 170 , 10 , 0 , 0 , 128 , 168 , 191 , 171 , 170 , 170 , 170 , 170 , 170 , 170 , 170 , 170 , 170 , 170 , 170 , 139 , 136 , 136 , 255 , 255 , 255 , 255 , 175 , 191 , 187 , 186 , 170 , 143 , 170 , 255 , 191 , 187 , 10 , 0 , 0 , 0 , 0 , 0 , 0 , 0 , 0 , 0 ,
0 , 0 , 0 , 80 , 85 , 5 , 0 , 0 , 0 , 0 , 93 , 85 , 85 , 85 , 17 , 17 , 17 , 17 , 17 , 17 , 21 , 17 , 81 , 85 , 0 , 0 , 255 , 223 , 223 , 221 , 95 , 85 , 85 , 85 , 85 , 5 , 0 , 85 , 85 , 85 , 1 , 0 , 0 , 0 , 0 , 0 , 0 , 0 , 0 , 0 ,
0 , 0 , 0 , 168 , 170 , 42 , 34 , 32 , 34 , 170 , 254 , 238 , 170 , 170 , 170 , 170 , 170 , 170 , 170 , 170 , 175 , 170 , 170 , 234 , 175 , 234 , 255 , 255 , 255 , 255 , 255 , 239 , 238 , 174 , 254 , 42 , 40 , 254 , 255 , 239 , 46 , 2 , 32 , 0 , 0 , 0 , 0 , 0 , 0 , 0 ,
0 , 0 , 0 , 84 , 85 , 5 , 0 , 0 , 0 , 64 , 84 , 85 , 85 , 85 , 85 , 85 , 85 , 85 , 85 , 85 , 85 , 85 , 85 , 68 , 85 , 245 , 127 , 255 , 255 , 255 , 95 , 87 , 85 , 85 , 85 , 1 , 0 , 84 , 87 , 85 , 5 , 0 , 0 , 0 , 0 , 0 , 0 , 0 , 0 , 0 ,
0 , 0 , 0 , 168 , 170 , 10 , 0 , 0 , 0 , 168 , 234 , 187 , 170 , 170 , 170 , 170 , 170 , 170 , 170 , 170 , 171 , 170 , 170 , 170 , 170 , 170 , 255 , 255 , 255 , 255 , 191 , 191 , 170 , 250 , 171 , 170 , 8 , 248 , 191 , 187 , 138 , 0 , 0 , 0 , 0 , 0 , 0 , 0 , 0 , 0 ,
0 , 0 , 0 , 80 , 85 , 1 , 0 , 0 , 0 , 0 , 64 , 85 , 85 , 85 , 69 , 85 , 17 , 17 , 17 , 85 , 85 , 17 , 17 , 85 , 17 , 209 , 255 , 253 , 255 , 255 , 95 , 85 , 85 , 85 , 85 , 1 , 0 , 80 , 85 , 85 , 5 , 0 , 0 , 0 , 0 , 0 , 0 , 0 , 0 , 0 ,
0 , 0 , 0 , 168 , 170 , 42 , 34 , 0 , 34 , 162 , 170 , 254 , 174 , 234 , 234 , 238 , 238 , 238 , 234 , 238 , 174 , 170 , 170 , 170 , 170 , 238 , 255 , 250 , 255 , 255 , 255 , 239 , 238 , 255 , 170 , 170 , 234 , 238 , 255 , 255 , 174 , 34 , 34 , 2 , 34 , 2 , 0 , 0 , 0 , 0 ,
0 , 0 , 0 , 84 , 85 , 5 , 0 , 0 , 0 , 0 , 0 , 116 , 85 , 85 , 69 , 85 , 85 , 85 , 85 , 85 , 85 , 85 , 85 , 85 , 85 , 213 , 127 , 80 , 255 , 85 , 95 , 87 , 85 , 87 , 85 , 69 , 80 , 85 , 85 , 85 , 5 , 0 , 0 , 0 , 0 , 0 , 0 , 0 , 0 , 0 ,
0 , 0 , 0 , 168 , 170 , 10 , 0 , 0 , 0 , 0 , 128 , 250 , 191 , 170 , 138 , 187 , 187 , 187 , 251 , 255 , 187 , 187 , 187 , 187 , 187 , 251 , 255 , 170 , 255 , 171 , 191 , 191 , 170 , 175 , 170 , 170 , 162 , 170 , 254 , 187 , 170 , 136 , 136 , 136 , 128 , 8 , 0 , 0 , 0 , 0 ,
0 , 0 , 0 , 16 , 85 , 1 , 0 , 0 , 0 , 0 , 0 , 208 , 85 , 85 , 21 , 85 , 21 , 85 , 85 , 85 , 85 , 85 , 85 , 85 , 85 , 253 , 127 , 0 , 253 , 21 , 81 , 93 , 85 , 21 , 84 , 17 , 64 , 21 , 85 , 85 , 21 , 0 , 0 , 0 , 0 , 0 , 0 , 0 , 0 , 0 ,
0 , 0 , 0 , 168 , 170 , 42 , 34 , 162 , 34 , 34 , 0 , 232 , 235 , 170 , 170 , 254 , 174 , 234 , 238 , 255 , 238 , 174 , 238 , 170 , 238 , 254 , 255 , 170 , 254 , 239 , 170 , 190 , 174 , 175 , 170 , 174 , 226 , 170 , 234 , 255 , 170 , 170 , 170 , 170 , 170 , 42 , 0 , 0 , 0 , 0 ,
0 , 0 , 0 , 84 , 85 , 5 , 16 , 0 , 0 , 0 , 0 , 0 , 7 , 85 , 21 , 85 , 85 , 85 , 116 , 119 , 85 , 85 , 85 , 85 , 85 , 253 , 127 , 69 , 117 , 87 , 5 , 85 , 85 , 87 , 85 , 69 , 64 , 85 , 85 , 85 , 85 , 0 , 0 , 0 , 0 , 0 , 0 , 0 , 0 , 0 ,
0 , 0 , 0 , 168 , 170 , 138 , 8 , 0 , 0 , 0 , 0 , 128 , 143 , 170 , 170 , 186 , 251 , 191 , 251 , 255 , 175 , 170 , 170 , 250 , 255 , 255 , 255 , 171 , 250 , 255 , 171 , 186 , 170 , 174 , 186 , 170 , 130 , 171 , 170 , 250 , 171 , 170 , 170 , 170 , 170 , 10 , 0 , 0 , 0 , 0 ,
0 , 0 , 0 , 80 , 85 , 1 , 16 , 0 , 0 , 0 , 0 , 0 , 20 , 84 , 85 , 85 , 85 , 85 , 213 , 85 , 85 , 85 , 85 , 253 , 223 , 213 , 255 , 31 , 85 , 85 , 85 , 81 , 85 , 21 , 85 , 21 , 64 , 21 , 1 , 84 , 21 , 0 , 0 , 0 , 0 , 0 , 0 , 0 , 0 , 0 ,
0 , 0 , 0 , 168 , 170 , 170 , 170 , 34 , 34 , 34 , 34 , 0 , 62 , 250 , 170 , 238 , 238 , 238 , 254 , 255 , 190 , 170 , 234 , 255 , 255 , 255 , 255 , 255 , 254 , 255 , 255 , 175 , 174 , 255 , 170 , 170 , 162 , 175 , 170 , 234 , 171 , 170 , 170 , 170 , 170 , 42 , 0 , 0 , 0 , 0 ,
0 , 0 , 0 , 84 , 85 , 69 , 68 , 0 , 0 , 0 , 0 , 0 , 80 , 80 , 85 , 85 , 85 , 85 , 117 , 87 , 85 , 85 , 85 , 255 , 255 , 255 , 255 , 255 , 87 , 117 , 119 , 87 , 85 , 119 , 85 , 85 , 64 , 85 , 68 , 68 , 85 , 68 , 68 , 68 , 68 , 4 , 0 , 0 , 0 , 0 ,
0 , 0 , 0 , 168 , 170 , 170 , 170 , 8 , 8 , 0 , 0 , 0 , 184 , 170 , 187 , 186 , 187 , 187 , 251 , 255 , 191 , 170 , 255 , 255 , 255 , 255 , 255 , 255 , 255 , 255 , 255 , 255 , 251 , 191 , 171 , 170 , 138 , 255 , 170 , 170 , 186 , 170 , 170 , 170 , 170 , 10 , 0 , 0 , 0 , 0 ,
0 , 0 , 0 , 16 , 17 , 17 , 21 , 0 , 0 , 0 , 0 , 0 , 80 , 65 , 85 , 81 , 85 , 85 , 85 , 85 , 85 , 213 , 255 , 255 , 93 , 85 , 213 , 255 , 255 , 255 , 221 , 85 , 85 , 93 , 85 , 21 , 0 , 85 , 1 , 0 , 16 , 0 , 0 , 0 , 0 , 0 , 0 , 0 , 0 , 0 ,
0 , 0 , 0 , 168 , 170 , 170 , 170 , 34 , 34 , 34 , 34 , 2 , 232 , 171 , 254 , 234 , 254 , 255 , 254 , 174 , 170 , 234 , 255 , 255 , 255 , 255 , 255 , 255 , 255 , 255 , 255 , 255 , 234 , 255 , 232 , 170 , 170 , 254 , 170 , 170 , 170 , 170 , 170 , 170 , 170 , 42 , 0 , 0 , 0 , 0 ,
0 , 0 , 0 , 84 , 85 , 85 , 85 , 1 , 0 , 0 , 0 , 0 , 64 , 5 , 84 , 85 , 85 , 85 , 117 , 85 , 85 , 85 , 255 , 255 , 119 , 119 , 247 , 255 , 255 , 255 , 255 , 87 , 85 , 119 , 81 , 85 , 4 , 85 , 68 , 68 , 68 , 68 , 68 , 64 , 68 , 4 , 0 , 0 , 0 , 0 ,
0 , 0 , 0 , 168 , 170 , 170 , 170 , 138 , 8 , 0 , 0 , 0 , 128 , 171 , 186 , 170 , 186 , 187 , 251 , 175 , 170 , 170 , 255 , 255 , 255 , 255 , 255 , 255 , 255 , 255 , 255 , 191 , 234 , 191 , 170 , 170 , 170 , 187 , 170 , 170 , 170 , 170 , 170 , 170 , 170 , 10 , 0 , 0 , 0 , 0 ,
0 , 0 , 0 , 20 , 17 , 81 , 85 , 1 , 0 , 0 , 0 , 0 , 0 , 20 , 84 , 85 , 84 , 85 , 93 , 85 , 85 , 85 , 81 , 221 , 223 , 85 , 221 , 253 , 255 , 255 , 255 , 95 , 85 , 93 , 85 , 21 , 0 , 85 , 20 , 1 , 0 , 0 , 0 , 0 , 0 , 0 , 0 , 0 , 0 , 0 ,
0 , 0 , 0 , 172 , 170 , 170 , 170 , 170 , 34 , 34 , 34 , 2 , 34 , 190 , 250 , 174 , 174 , 254 , 254 , 175 , 170 , 170 , 234 , 238 , 255 , 255 , 255 , 255 , 255 , 255 , 255 , 255 , 238 , 254 , 238 , 170 , 170 , 238 , 170 , 170 , 170 , 170 , 170 , 170 , 170 , 42 , 0 , 0 , 0 , 0 ,
0 , 0 , 0 , 84 , 85 , 85 , 85 , 5 , 0 , 0 , 0 , 0 , 0 , 80 , 112 , 85 , 21 , 85 , 117 , 85 , 85 , 85 , 85 , 85 , 85 , 255 , 255 , 255 , 255 , 255 , 255 , 127 , 85 , 85 , 85 , 69 , 69 , 85 , 80 , 68 , 68 , 68 , 68 , 68 , 68 , 4 , 0 , 0 , 0 , 0 ,
0 , 0 , 0 , 168 , 170 , 170 , 170 , 138 , 8 , 0 , 0 , 0 , 128 , 168 , 251 , 171 , 170 , 187 , 251 , 191 , 170 , 170 , 186 , 171 , 186 , 251 , 255 , 255 , 255 , 255 , 255 , 255 , 191 , 186 , 170 , 170 , 170 , 174 , 168 , 170 , 170 , 170 , 170 , 170 , 170 , 10 , 0 , 0 , 0 , 0 ,
0 , 0 , 0 , 16 , 17 , 21 , 21 , 5 , 0 , 0 , 0 , 0 , 0 , 64 , 85 , 85 , 85 , 85 , 85 , 85 , 85 , 85 , 85 , 85 , 85 , 221 , 255 , 255 , 255 , 255 , 255 , 255 , 93 , 17 , 21 , 85 , 21 , 85 , 81 , 17 , 0 , 0 , 0 , 0 , 0 , 0 , 0 , 0 , 0 , 0 ,
0 , 0 , 0 , 184 , 170 , 170 , 170 , 170 , 42 , 34 , 34 , 0 , 34 , 234 , 254 , 239 , 234 , 239 , 254 , 175 , 170 , 234 , 174 , 238 , 254 , 255 , 255 , 255 , 255 , 255 , 255 , 255 , 255 , 170 , 170 , 174 , 170 , 254 , 227 , 170 , 170 , 170 , 170 , 170 , 170 , 42 , 0 , 0 , 0 , 0 ,
0 , 0 , 0 , 84 , 85 , 85 , 85 , 21 , 0 , 0 , 0 , 0 , 0 , 64 , 116 , 85 , 85 , 84 , 117 , 85 , 85 , 85 , 85 , 85 , 85 , 85 , 117 , 119 , 255 , 255 , 255 , 255 , 119 , 84 , 85 , 85 , 85 , 85 , 69 , 69 , 68 , 68 , 68 , 68 , 68 , 4 , 0 , 0 , 0 , 0 ,
0 , 0 , 0 , 184 , 170 , 170 , 170 , 170 , 136 , 0 , 234 , 0 , 0 , 0 , 232 , 171 , 170 , 184 , 251 , 187 , 170 , 190 , 186 , 170 , 187 , 170 , 255 , 255 , 255 , 255 , 255 , 255 , 255 , 170 , 170 , 170 , 170 , 190 , 138 , 170 , 170 , 170 , 170 , 170 , 170 , 42 , 0 , 0 , 0 , 0 ,
0 , 0 , 0 , 80 , 17 , 81 , 85 , 21 , 17 , 0 , 252 , 1 , 0 , 0 , 192 , 85 , 85 , 81 , 85 , 85 , 85 , 85 , 85 , 85 , 85 , 85 , 85 , 221 , 255 , 221 , 221 , 221 , 95 , 21 , 81 , 21 , 21 , 85 , 1 , 17 , 17 , 17 , 17 , 1 , 16 , 17 , 0 , 0 , 0 , 0 ,
0 , 0 , 0 , 232 , 170 , 170 , 170 , 170 , 250 , 34 , 254 , 39 , 34 , 34 , 226 , 239 , 170 , 250 , 255 , 254 , 234 , 186 , 255 , 238 , 238 , 238 , 238 , 238 , 255 , 255 , 255 , 255 , 255 , 175 , 234 , 174 , 170 , 238 , 170 , 175 , 170 , 170 , 170 , 170 , 170 , 42 , 0 , 0 , 0 , 0 ,
0 , 0 , 0 , 84 , 85 , 85 , 85 , 85 , 85 , 1 , 254 , 7 , 0 , 0 , 64 , 87 , 85 , 85 , 117 , 85 , 85 , 85 , 85 , 85 , 85 , 85 , 85 , 85 , 85 , 85 , 87 , 245 , 127 , 69 , 84 , 85 , 85 , 85 , 5 , 87 , 68 , 68 , 68 , 68 , 84 , 4 , 0 , 0 , 0 , 0 ,
0 , 0 , 0 , 168 , 170 , 170 , 170 , 170 , 250 , 11 , 254 , 143 , 0 , 0 , 128 , 175 , 170 , 186 , 250 , 139 , 170 , 234 , 186 , 171 , 170 , 170 , 250 , 186 , 187 , 255 , 255 , 255 , 255 , 175 , 170 , 191 , 170 , 186 , 15 , 250 , 170 , 170 , 170 , 170 , 170 , 42 , 0 , 0 , 0 , 0 ,
0 , 0 , 0 , 80 , 17 , 17 , 17 , 81 , 85 , 5 , 252 , 15 , 0 , 0 , 0 , 85 , 85 , 85 , 213 , 5 , 81 , 85 , 85 , 85 , 85 , 85 , 85 , 221 , 221 , 221 , 221 , 221 , 253 , 21 , 81 , 93 , 81 , 81 , 7 , 84 , 21 , 17 , 17 , 17 , 17 , 17 , 0 , 0 , 0 , 0 ,
0 , 0 , 0 , 232 , 170 , 170 , 170 , 170 , 170 , 46 , 250 , 15 , 34 , 34 , 162 , 238 , 170 , 250 , 234 , 175 , 234 , 170 , 254 , 238 , 238 , 238 , 255 , 255 , 255 , 255 , 255 , 255 , 255 , 255 , 234 , 255 , 238 , 250 , 46 , 174 , 174 , 170 , 170 , 170 , 170 , 42 , 0 , 0 , 0 , 0 ,
0 , 0 , 0 , 84 , 85 , 85 , 85 , 85 , 69 , 28 , 248 , 31 , 0 , 0 , 0 , 84 , 85 , 85 , 85 , 85 , 84 , 84 , 85 , 85 , 85 , 85 , 255 , 255 , 127 , 119 , 245 , 255 , 255 , 119 , 69 , 119 , 85 , 117 , 21 , 84 , 84 , 68 , 68 , 68 , 84 , 20 , 0 , 0 , 0 , 0 ,
0 , 0 , 0 , 184 , 170 , 170 , 170 , 170 , 170 , 186 , 248 , 31 , 0 , 0 , 128 , 186 , 170 , 170 , 251 , 191 , 170 , 187 , 186 , 187 , 186 , 255 , 255 , 191 , 170 , 186 , 235 , 255 , 255 , 255 , 171 , 255 , 175 , 235 , 138 , 174 , 234 , 170 , 170 , 170 , 170 , 42 , 0 , 0 , 0 , 0 ,
0 , 0 , 0 , 80 , 17 , 17 , 81 , 81 , 21 , 17 , 240 , 31 , 0 , 0 , 0 , 80 , 85 , 85 , 213 , 21 , 17 , 85 , 84 , 85 , 85 , 221 , 21 , 1 , 0 , 64 , 208 , 221 , 253 , 223 , 85 , 93 , 21 , 81 , 21 , 20 , 85 , 21 , 17 , 17 , 17 , 17 , 0 , 0 , 0 , 0 ,
0 , 0 , 0 , 232 , 170 , 170 , 170 , 170 , 170 , 58 , 226 , 63 , 34 , 34 , 162 , 250 , 174 , 254 , 239 , 191 , 170 , 234 , 254 , 238 , 254 , 255 , 171 , 170 , 170 , 234 , 234 , 255 , 255 , 255 , 191 , 254 , 174 , 234 , 46 , 190 , 174 , 174 , 170 , 170 , 170 , 42 , 0 , 0 , 0 , 0 ,
0 , 0 , 0 , 84 , 85 , 85 , 85 , 85 , 85 , 117 , 192 , 127 , 0 , 0 , 0 , 112 , 85 , 85 , 85 , 85 , 84 , 85 , 85 , 85 , 85 , 85 , 69 , 4 , 0 , 64 , 112 , 95 , 245 , 255 , 95 , 85 , 85 , 84 , 21 , 84 , 69 , 85 , 68 , 68 , 84 , 21 , 0 , 0 , 0 , 0 ,
0 , 0 , 0 , 168 , 171 , 170 , 170 , 170 , 170 , 170 , 128 , 255 , 128 , 0 , 128 , 248 , 171 , 191 , 235 , 187 , 170 , 186 , 170 , 187 , 187 , 251 , 170 , 170 , 138 , 138 , 248 , 191 , 251 , 255 , 255 , 187 , 174 , 170 , 138 , 250 , 171 , 251 , 170 , 170 , 170 , 42 , 0 , 0 , 0 , 0 ,
0 , 0 , 0 , 80 , 21 , 17 , 17 , 81 , 85 , 85 , 0 , 252 , 1 , 0 , 0 , 80 , 85 , 85 , 85 , 85 , 17 , 85 , 85 , 85 , 85 , 117 , 1 , 0 , 0 , 0 , 80 , 95 , 85 , 253 , 87 , 85 , 85 , 20 , 21 , 80 , 85 , 85 , 21 , 17 , 17 , 17 , 0 , 0 , 0 , 0 ,
0 , 0 , 0 , 168 , 175 , 170 , 170 , 170 , 170 , 234 , 34 , 250 , 163 , 34 , 34 , 234 , 239 , 255 , 255 , 255 , 170 , 174 , 170 , 254 , 255 , 254 , 170 , 170 , 170 , 170 , 226 , 239 , 255 , 255 , 255 , 175 , 238 , 235 , 174 , 250 , 238 , 174 , 174 , 170 , 170 , 42 , 0 , 0 , 0 , 0 ,
0 , 0 , 0 , 84 , 85 , 85 , 85 , 85 , 85 , 85 , 0 , 64 , 23 , 0 , 0 , 64 , 85 , 85 , 117 , 119 , 85 , 85 , 85 , 85 , 85 , 117 , 68 , 0 , 0 , 0 , 208 , 87 , 245 , 255 , 127 , 85 , 85 , 69 , 21 , 84 , 85 , 85 , 85 , 68 , 84 , 20 , 0 , 0 , 0 , 0 ,
0 , 0 , 0 , 168 , 190 , 170 , 170 , 170 , 170 , 170 , 136 , 3 , 186 , 0 , 0 , 232 , 171 , 187 , 250 , 191 , 170 , 170 , 170 , 170 , 187 , 187 , 170 , 170 , 136 , 136 , 240 , 175 , 255 , 255 , 255 , 171 , 254 , 171 , 170 , 250 , 187 , 186 , 171 , 170 , 170 , 42 , 0 , 0 , 0 , 0 ,
0 , 0 , 0 , 16 , 85 , 17 , 17 , 17 , 21 , 85 , 193 , 1 , 16 , 0 , 0 , 64 , 85 , 85 , 209 , 85 , 85 , 85 , 85 , 85 , 85 , 85 , 1 , 0 , 0 , 0 , 208 , 215 , 221 , 253 , 255 , 85 , 85 , 85 , 21 , 84 , 85 , 85 , 21 , 17 , 17 , 17 , 0 , 0 , 0 , 0 ,
0 , 0 , 0 , 168 , 250 , 170 , 170 , 170 , 170 , 234 , 235 , 46 , 234 , 34 , 34 , 234 , 239 , 255 , 239 , 255 , 170 , 170 , 170 , 238 , 238 , 190 , 170 , 170 , 170 , 170 , 234 , 235 , 255 , 255 , 255 , 255 , 255 , 191 , 174 , 254 , 238 , 255 , 175 , 174 , 170 , 42 , 0 , 0 , 0 , 0 ,
0 , 0 , 0 , 84 , 117 , 85 , 85 , 85 , 85 , 85 , 5 , 15 , 84 , 0 , 0 , 64 , 85 , 117 , 119 , 87 , 85 , 85 , 85 , 85 , 85 , 117 , 4 , 0 , 0 , 0 , 244 , 69 , 255 , 255 , 255 , 127 , 119 , 87 , 85 , 84 , 85 , 85 , 85 , 84 , 84 , 4 , 0 , 0 , 0 , 0 ,
0 , 0 , 0 , 168 , 170 , 170 , 170 , 170 , 170 , 170 , 139 , 15 , 168 , 0 , 0 , 136 , 187 , 250 , 255 , 191 , 171 , 170 , 170 , 170 , 170 , 187 , 170 , 170 , 136 , 136 , 250 , 234 , 255 , 255 , 255 , 255 , 255 , 191 , 170 , 254 , 187 , 187 , 186 , 171 , 170 , 42 , 0 , 0 , 0 , 0 ,
0 , 0 , 0 , 16 , 17 , 17 , 17 , 17 , 85 , 81 , 21 , 0 , 84 , 0 , 0 , 0 , 85 , 193 , 93 , 85 , 85 , 85 , 85 , 85 , 85 , 93 , 1 , 0 , 0 , 0 , 80 , 208 , 221 , 253 , 255 , 255 , 221 , 85 , 21 , 85 , 85 , 85 , 85 , 5 , 17 , 17 , 0 , 0 , 0 , 0 ,
0 , 0 , 0 , 168 , 170 , 170 , 170 , 170 , 170 , 170 , 190 , 2 , 170 , 34 , 34 , 162 , 255 , 234 , 255 , 255 , 255 , 174 , 174 , 234 , 238 , 255 , 170 , 170 , 170 , 170 , 170 , 234 , 255 , 255 , 255 , 255 , 254 , 255 , 170 , 255 , 255 , 174 , 238 , 175 , 174 , 42 , 0 , 0 , 0 , 0 ,
0 , 0 , 0 , 84 , 85 , 85 , 85 , 85 , 85 , 85 , 85 , 1 , 84 , 0 , 0 , 0 , 85 , 69 , 255 , 127 , 255 , 85 , 85 , 85 , 85 , 117 , 4 , 0 , 0 , 0 , 84 , 112 , 247 , 255 , 255 , 127 , 117 , 87 , 68 , 85 , 85 , 64 , 85 , 85 , 84 , 4 , 0 , 0 , 0 , 0 ,
0 , 0 , 0 , 168 , 170 , 170 , 170 , 170 , 170 , 170 , 250 , 3 , 168 , 0 , 0 , 128 , 187 , 170 , 255 , 255 , 255 , 191 , 170 , 170 , 170 , 250 , 170 , 170 , 136 , 136 , 136 , 248 , 255 , 255 , 255 , 191 , 234 , 186 , 170 , 170 , 170 , 170 , 187 , 187 , 184 , 42 , 0 , 0 , 0 , 0 ,
0 , 0 , 0 , 16 , 17 , 85 , 21 , 17 , 17 , 17 , 81 , 0 , 20 , 0 , 0 , 0 , 85 , 17 , 221 , 221 , 255 , 95 , 85 , 85 , 85 , 85 , 0 , 0 , 0 , 0 , 0 , 208 , 221 , 221 , 255 , 31 , 81 , 81 , 17 , 0 , 0 , 85 , 85 , 85 , 65 , 17 , 0 , 0 , 0 , 0 ,
0 , 0 , 0 , 168 , 170 , 170 , 170 , 170 , 170 , 170 , 250 , 34 , 170 , 34 , 34 , 162 , 255 , 42 , 255 , 255 , 255 , 255 , 175 , 238 , 174 , 254 , 170 , 170 , 170 , 170 , 170 , 250 , 255 , 255 , 255 , 191 , 234 , 234 , 174 , 170 , 234 , 255 , 255 , 255 , 175 , 43 , 0 , 0 , 0 , 0 ,
0 , 0 , 0 , 84 , 85 , 85 , 85 , 85 , 85 , 85 , 117 , 85 , 84 , 0 , 0 , 0 , 117 , 69 , 255 , 255 , 255 , 95 , 85 , 85 , 85 , 125 , 4 , 0 , 0 , 0 , 0 , 116 , 255 , 255 , 247 , 95 , 116 , 69 , 85 , 85 , 117 , 85 , 85 , 85 , 21 , 7 , 0 , 0 , 0 , 0 ,
0 , 0 , 0 , 168 , 170 , 170 , 170 , 170 , 170 , 170 , 250 , 171 , 170 , 0 , 0 , 128 , 251 , 171 , 254 , 255 , 255 , 191 , 171 , 170 , 186 , 255 , 170 , 170 , 136 , 136 , 136 , 250 , 255 , 255 , 255 , 191 , 250 , 234 , 255 , 251 , 255 , 191 , 187 , 187 , 187 , 46 , 0 , 0 , 0 , 0 ,
0 , 0 , 0 , 16 , 17 , 81 , 21 , 21 , 85 , 21 , 81 , 85 , 85 , 0 , 0 , 0 , 85 , 21 , 220 , 93 , 85 , 93 , 17 , 84 , 85 , 221 , 1 , 0 , 0 , 0 , 0 , 84 , 221 , 221 , 221 , 93 , 221 , 213 , 95 , 213 , 255 , 85 , 85 , 85 , 85 , 17 , 0 , 0 , 0 , 0 ,
0 , 0 , 0 , 168 , 170 , 170 , 170 , 170 , 170 , 170 , 250 , 175 , 170 , 34 , 34 , 162 , 254 , 174 , 254 , 255 , 255 , 175 , 170 , 170 , 254 , 255 , 170 , 170 , 170 , 170 , 170 , 238 , 255 , 255 , 255 , 255 , 255 , 255 , 255 , 255 , 255 , 255 , 255 , 255 , 255 , 42 , 0 , 0 , 0 , 0 ,
0 , 0 , 0 , 84 , 85 , 85 , 85 , 85 , 85 , 85 , 117 , 85 , 85 , 0 , 0 , 0 , 85 , 85 , 116 , 119 , 119 , 85 , 4 , 80 , 117 , 255 , 5 , 0 , 0 , 0 , 0 , 117 , 255 , 255 , 255 , 255 , 255 , 255 , 255 , 255 , 255 , 127 , 85 , 85 , 85 , 5 , 0 , 0 , 0 , 0 ,
0 , 0 , 0 , 168 , 170 , 170 , 170 , 170 , 170 , 170 , 170 , 186 , 170 , 0 , 0 , 128 , 234 , 170 , 254 , 255 , 255 , 175 , 10 , 160 , 234 , 255 , 171 , 138 , 136 , 136 , 168 , 255 , 255 , 255 , 255 , 255 , 255 , 255 , 255 , 255 , 255 , 255 , 191 , 187 , 187 , 43 , 0 , 0 , 0 , 0 ,
0 , 0 , 0 , 16 , 17 , 81 , 21 , 81 , 21 , 17 , 17 , 85 , 85 , 0 , 0 , 0 , 84 , 85 , 85 , 221 , 85 , 21 , 1 , 64 , 213 , 223 , 1 , 0 , 0 , 0 , 0 , 213 , 221 , 253 , 221 , 221 , 221 , 253 , 255 , 223 , 223 , 221 , 93 , 85 , 85 , 21 , 0 , 0 , 0 , 0 ,
0 , 0 , 0 , 168 , 170 , 170 , 170 , 170 , 170 , 170 , 170 , 170 , 42 , 34 , 34 , 34 , 174 , 175 , 254 , 255 , 255 , 175 , 42 , 160 , 238 , 255 , 171 , 170 , 170 , 170 , 170 , 255 , 255 , 255 , 255 , 255 , 255 , 255 , 255 , 255 , 255 , 255 , 255 , 255 , 255 , 63 , 0 , 0 , 0 , 0 ,
0 , 0 , 0 , 84 , 85 , 85 , 85 , 85 , 85 , 85 , 85 , 85 , 21 , 0 , 0 , 0 , 84 , 84 , 85 , 253 , 119 , 85 , 5 , 64 , 245 , 255 , 7 , 0 , 0 , 0 , 64 , 245 , 255 , 255 , 255 , 255 , 255 , 255 , 255 , 85 , 255 , 255 , 255 , 87 , 85 , 21 , 0 , 0 , 0 , 0 ,
0 , 0 , 0 , 168 , 170 , 170 , 170 , 170 , 170 , 170 , 170 , 170 , 42 , 0 , 0 , 0 , 184 , 170 , 186 , 251 , 255 , 191 , 187 , 128 , 254 , 255 , 175 , 170 , 136 , 136 , 232 , 255 , 255 , 255 , 255 , 255 , 255 , 255 , 255 , 170 , 250 , 255 , 255 , 255 , 255 , 59 , 0 , 0 , 0 , 0 ,
0 , 0 , 0 , 20 , 17 , 81 , 85 , 21 , 85 , 17 , 81 , 17 , 17 , 0 , 0 , 0 , 84 , 80 , 81 , 213 , 255 , 21 , 0 , 5 , 213 , 221 , 5 , 0 , 0 , 0 , 208 , 221 , 221 , 221 , 221 , 221 , 221 , 221 , 221 , 17 , 81 , 221 , 221 , 221 , 93 , 21 , 0 , 0 , 0 , 0 ,
0 , 0 , 0 , 168 , 170 , 170 , 170 , 170 , 170 , 170 , 170 , 170 , 42 , 34 , 34 , 34 , 234 , 170 , 250 , 238 , 255 , 171 , 2 , 168 , 255 , 255 , 175 , 170 , 170 , 171 , 234 , 255 , 255 , 255 , 255 , 255 , 255 , 255 , 255 , 170 , 170 , 234 , 255 , 255 , 255 , 63 , 0 , 0 , 0 , 0 ,
0 , 0 , 0 , 84 , 85 , 85 , 85 , 85 , 85 , 85 , 85 , 85 , 5 , 0 , 0 , 0 , 84 , 65 , 117 , 85 , 127 , 85 , 0 , 64 , 247 , 255 , 95 , 0 , 0 , 7 , 80 , 119 , 255 , 255 , 255 , 255 , 255 , 255 , 117 , 69 , 68 , 69 , 245 , 255 , 255 , 23 , 0 , 0 , 0 , 0 ,
0 , 0 , 0 , 168 , 170 , 170 , 170 , 170 , 170 , 170 , 170 , 170 , 138 , 0 , 0 , 0 , 168 , 139 , 234 , 171 , 255 , 186 , 10 , 136 , 255 , 255 , 255 , 170 , 136 , 175 , 248 , 255 , 255 , 255 , 255 , 255 , 255 , 255 , 251 , 170 , 170 , 170 , 170 , 255 , 255 , 63 , 0 , 0 , 0 , 0 ,
0 , 0 , 0 , 84 , 17 , 81 , 85 , 85 , 85 , 85 , 81 , 17 , 1 , 0 , 0 , 0 , 80 , 5 , 69 , 85 , 125 , 85 , 21 , 0 , 221 , 221 , 221 , 1 , 0 , 29 , 212 , 221 , 221 , 221 , 221 , 221 , 221 , 93 , 93 , 17 , 17 , 17 , 1 , 80 , 221 , 29 , 0 , 0 , 0 , 0 ,
0 , 0 , 0 , 172 , 170 , 170 , 170 , 170 , 170 , 170 , 170 , 170 , 42 , 34 , 34 , 34 , 234 , 174 , 238 , 239 , 254 , 255 , 255 , 160 , 255 , 255 , 255 , 171 , 170 , 63 , 250 , 255 , 255 , 255 , 255 , 255 , 255 , 255 , 190 , 170 , 170 , 170 , 170 , 170 , 254 , 63 , 0 , 0 , 0 , 0 ,
0 , 0 , 0 , 84 , 85 , 85 , 85 , 85 , 85 , 85 , 85 , 69 , 5 , 0 , 0 , 0 , 80 , 5 , 84 , 119 , 255 , 255 , 255 , 65 , 255 , 255 , 255 , 71 , 64 , 93 , 244 , 255 , 255 , 255 , 119 , 119 , 119 , 119 , 95 , 68 , 85 , 85 , 68 , 68 , 68 , 21 , 0 , 0 , 0 , 0 ,
0 , 0 , 0 , 184 , 170 , 170 , 170 , 170 , 170 , 170 , 170 , 170 , 138 , 0 , 0 , 160 , 168 , 186 , 184 , 255 , 191 , 255 , 255 , 171 , 255 , 255 , 255 , 191 , 186 , 191 , 250 , 255 , 255 , 255 , 255 , 255 , 255 , 191 , 191 , 170 , 170 , 170 , 170 , 170 , 170 , 42 , 0 , 0 , 0 , 0 ,
0 , 0 , 0 , 84 , 85 , 17 , 17 , 85 , 85 , 85 , 17 , 17 , 1 , 0 , 0 , 64 , 80 , 21 , 80 , 85 , 85 , 81 , 221 , 85 , 255 , 253 , 255 , 31 , 64 , 29 , 209 , 221 , 221 , 221 , 221 , 221 , 85 , 213 , 29 , 16 , 21 , 17 , 17 , 17 , 17 , 16 , 0 , 0 , 0 , 0 ,
0 , 0 , 0 , 236 , 174 , 170 , 170 , 170 , 170 , 170 , 170 , 170 , 34 , 34 , 34 , 226 , 234 , 234 , 234 , 255 , 174 , 42 , 250 , 255 , 255 , 255 , 255 , 255 , 162 , 190 , 250 , 255 , 255 , 255 , 255 , 255 , 255 , 255 , 175 , 170 , 170 , 170 , 170 , 170 , 170 , 42 , 0 , 0 , 0 , 0 ,
0 , 0 , 0 , 84 , 85 , 85 , 85 , 85 , 85 , 85 , 85 , 68 , 1 , 0 , 0 , 64 , 84 , 85 , 64 , 85 , 85 , 0 , 64 , 215 , 255 , 255 , 255 , 127 , 0 , 95 , 84 , 255 , 255 , 255 , 119 , 119 , 119 , 119 , 71 , 68 , 84 , 85 , 85 , 85 , 69 , 4 , 0 , 0 , 0 , 0 ,
0 , 0 , 0 , 184 , 170 , 170 , 170 , 170 , 170 , 170 , 170 , 170 , 138 , 0 , 0 , 160 , 170 , 170 , 138 , 254 , 171 , 8 , 128 , 255 , 255 , 255 , 255 , 255 , 139 , 174 , 234 , 255 , 255 , 255 , 255 , 255 , 255 , 191 , 171 , 170 , 170 , 170 , 170 , 170 , 170 , 42 , 0 , 0 , 0 , 0 ,
0 , 0 , 0 , 84 , 85 , 17 , 17 , 85 , 85 , 85 , 21 , 17 , 1 , 0 , 0 , 64 , 81 , 21 , 1 , 84 , 21 , 0 , 0 , 212 , 253 , 221 , 253 , 255 , 17 , 23 , 209 , 253 , 253 , 221 , 221 , 93 , 213 , 93 , 1 , 0 , 80 , 85 , 17 , 17 , 17 , 17 , 0 , 0 , 0 , 0 ,
0 , 0 , 0 , 236 , 174 , 170 , 170 , 170 , 170 , 170 , 170 , 170 , 34 , 34 , 34 , 162 , 234 , 170 , 174 , 250 , 175 , 2 , 0 , 254 , 255 , 255 , 255 , 255 , 175 , 175 , 170 , 255 , 255 , 255 , 255 , 255 , 255 , 255 , 170 , 170 , 170 , 170 , 170 , 170 , 170 , 42 , 0 , 0 , 0 , 0 ,
0 , 0 , 0 , 84 , 85 , 85 , 85 , 85 , 85 , 85 , 85 , 69 , 0 , 0 , 0 , 80 , 85 , 85 , 4 , 80 , 5 , 0 , 0 , 252 , 255 , 255 , 255 , 255 , 247 , 87 , 85 , 255 , 255 , 255 , 127 , 119 , 255 , 85 , 4 , 0 , 64 , 85 , 85 , 85 , 85 , 21 , 0 , 0 , 0 , 0 ,
0 , 0 , 0 , 184 , 170 , 170 , 170 , 170 , 170 , 170 , 170 , 170 , 136 , 0 , 0 , 168 , 170 , 170 , 170 , 168 , 139 , 0 , 0 , 248 , 255 , 255 , 255 , 255 , 255 , 171 , 191 , 255 , 255 , 255 , 255 , 255 , 255 , 235 , 170 , 138 , 136 , 170 , 170 , 170 , 170 , 42 , 0 , 0 , 0 , 0 ,
0 , 0 , 0 , 84 , 85 , 21 , 17 , 85 , 85 , 85 , 85 , 17 , 0 , 0 , 0 , 80 , 85 , 17 , 1 , 0 , 17 , 0 , 0 , 240 , 223 , 221 , 253 , 255 , 95 , 85 , 93 , 253 , 221 , 253 , 253 , 255 , 93 , 81 , 1 , 0 , 0 , 16 , 17 , 17 , 17 , 17 , 0 , 0 , 0 , 0 ,
0 , 0 , 0 , 236 , 174 , 170 , 170 , 170 , 170 , 170 , 170 , 170 , 34 , 34 , 34 , 170 , 234 , 170 , 170 , 42 , 42 , 2 , 0 , 250 , 255 , 255 , 255 , 255 , 255 , 238 , 255 , 255 , 255 , 255 , 255 , 255 , 255 , 187 , 170 , 170 , 170 , 170 , 170 , 170 , 170 , 42 , 0 , 0 , 0 , 0 ,
0 , 0 , 0 , 84 , 85 , 85 , 85 , 85 , 85 , 85 , 85 , 85 , 0 , 0 , 0 , 84 , 85 , 85 , 4 , 0 , 4 , 0 , 0 , 116 , 117 , 255 , 247 , 255 , 255 , 213 , 255 , 215 , 127 , 127 , 119 , 119 , 87 , 85 , 0 , 0 , 0 , 64 , 85 , 85 , 85 , 21 , 0 , 0 , 0 , 0 ,
0 , 0 , 0 , 184 , 171 , 170 , 170 , 170 , 170 , 170 , 170 , 170 , 138 , 0 , 0 , 168 , 170 , 170 , 170 , 170 , 168 , 0 , 0 , 254 , 251 , 255 , 255 , 255 , 255 , 235 , 255 , 191 , 255 , 255 , 255 , 255 , 255 , 174 , 138 , 136 , 136 , 168 , 170 , 170 , 170 , 42 , 0 , 0 , 0 , 0 ,
0 , 0 , 0 , 84 , 85 , 85 , 21 , 81 , 85 , 85 , 21 , 17 , 0 , 0 , 0 , 84 , 85 , 17 , 1 , 0 , 0 , 0 , 0 , 212 , 69 , 85 , 213 , 221 , 255 , 221 , 223 , 93 , 221 , 221 , 93 , 85 , 85 , 21 , 0 , 0 , 0 , 0 , 81 , 17 , 17 , 17 , 0 , 0 , 0 , 0 ,
0 , 0 , 0 , 236 , 238 , 170 , 170 , 170 , 170 , 170 , 170 , 170 , 170 , 34 , 34 , 170 , 234 , 170 , 170 , 170 , 34 , 2 , 128 , 234 , 175 , 255 , 255 , 255 , 255 , 255 , 255 , 255 , 255 , 255 , 255 , 255 , 255 , 187 , 170 , 170 , 162 , 162 , 170 , 170 , 170 , 42 , 0 , 0 , 0 , 0 ,
0 , 0 , 0 , 84 , 85 , 85 , 84 , 85 , 85 , 85 , 85 , 69 , 0 , 0 , 0 , 84 , 85 , 85 , 0 , 64 , 0 , 0 , 0 , 69 , 87 , 84 , 119 , 245 , 255 , 255 , 255 , 127 , 247 , 127 , 119 , 119 , 213 , 69 , 0 , 0 , 0 , 0 , 84 , 85 , 85 , 21 , 0 , 0 , 0 , 0 ,
0 , 0 , 0 , 184 , 171 , 170 , 170 , 170 , 170 , 170 , 170 , 170 , 170 , 128 , 0 , 170 , 170 , 170 , 170 , 170 , 10 , 8 , 128 , 171 , 190 , 186 , 251 , 255 , 255 , 255 , 255 , 255 , 255 , 255 , 255 , 255 , 255 , 174 , 138 , 136 , 136 , 136 , 170 , 170 , 170 , 42 , 0 , 0 , 0 , 0 ,
0 , 0 , 0 , 80 , 85 , 85 , 17 , 81 , 81 , 85 , 85 , 17 , 0 , 0 , 0 , 80 , 85 , 17 , 1 , 0 , 1 , 0 , 0 , 21 , 80 , 81 , 85 , 213 , 253 , 223 , 221 , 221 , 85 , 221 , 221 , 85 , 85 , 1 , 0 , 0 , 0 , 0 , 80 , 17 , 17 , 17 , 0 , 0 , 0 , 0 ,
0 , 0 , 0 , 232 , 174 , 170 , 170 , 170 , 170 , 170 , 170 , 170 , 170 , 170 , 34 , 170 , 234 , 170 , 170 , 170 , 42 , 128 , 160 , 170 , 170 , 174 , 238 , 255 , 255 , 255 , 255 , 255 , 255 , 255 , 255 , 255 , 255 , 171 , 170 , 170 , 162 , 34 , 170 , 170 , 170 , 42 , 0 , 0 , 0 , 0 ,
0 , 0 , 0 , 84 , 85 , 85 , 85 , 85 , 85 , 85 , 85 , 69 , 68 , 64 , 64 , 80 , 85 , 85 , 4 , 0 , 20 , 0 , 64 , 85 , 0 , 84 , 85 , 87 , 255 , 255 , 255 , 127 , 119 , 119 , 119 , 85 , 247 , 7 , 0 , 0 , 0 , 0 , 64 , 85 , 85 , 21 , 0 , 0 , 0 , 0 ,
0 , 0 , 0 , 184 , 171 , 170 , 170 , 170 , 170 , 170 , 170 , 170 , 170 , 170 , 170 , 160 , 170 , 170 , 170 , 170 , 170 , 0 , 170 , 170 , 170 , 184 , 187 , 191 , 255 , 255 , 255 , 255 , 255 , 255 , 255 , 255 , 255 , 175 , 136 , 136 , 136 , 136 , 136 , 170 , 170 , 42 , 0 , 0 , 0 , 0 ,
0 , 0 , 0 , 80 , 21 , 85 , 17 , 17 , 17 , 85 , 85 , 17 , 17 , 81 , 65 , 64 , 85 , 17 , 0 , 0 , 16 , 0 , 80 , 21 , 1 , 80 , 85 , 85 , 125 , 221 , 253 , 221 , 85 , 85 , 85 , 85 , 253 , 29 , 0 , 0 , 0 , 0 , 0 , 17 , 17 , 17 , 0 , 0 , 0 , 0 ,
0 , 0 , 0 , 248 , 174 , 170 , 170 , 170 , 170 , 170 , 170 , 170 , 170 , 170 , 234 , 224 , 174 , 170 , 170 , 170 , 170 , 2 , 224 , 174 , 170 , 170 , 175 , 238 , 255 , 255 , 255 , 255 , 255 , 255 , 255 , 255 , 255 , 255 , 170 , 42 , 162 , 34 , 162 , 170 , 170 , 42 , 0 , 0 , 0 , 0 ,
0 , 0 , 0 , 84 , 85 , 85 , 85 , 85 , 85 , 85 , 85 , 68 , 84 , 85 , 69 , 65 , 85 , 85 , 68 , 0 , 68 , 5 , 64 , 85 , 68 , 4 , 5 , 84 , 247 , 247 , 255 , 255 , 119 , 119 , 85 , 245 , 255 , 95 , 1 , 0 , 0 , 0 , 0 , 84 , 85 , 21 , 0 , 0 , 0 , 0 ,
0 , 0 , 0 , 184 , 170 , 170 , 170 , 170 , 170 , 170 , 170 , 170 , 170 , 170 , 170 , 163 , 187 , 170 , 170 , 170 , 170 , 10 , 128 , 170 , 170 , 170 , 168 , 232 , 255 , 255 , 255 , 255 , 255 , 255 , 255 , 255 , 255 , 191 , 138 , 136 , 136 , 8 , 136 , 168 , 170 , 42 , 0 , 0 , 0 , 0 ,
0 , 0 , 0 , 84 , 21 , 85 , 17 , 21 , 85 , 85 , 85 , 16 , 17 , 5 , 85 , 65 , 85 , 85 , 0 , 0 , 0 , 21 , 0 , 20 , 1 , 0 , 0 , 64 , 85 , 93 , 221 , 221 , 223 , 93 , 221 , 253 , 223 , 93 , 21 , 0 , 0 , 0 , 0 , 0 , 17 , 17 , 0 , 0 , 0 , 0 ,
0 , 0 , 0 , 236 , 174 , 170 , 170 , 170 , 170 , 170 , 170 , 170 , 170 , 10 , 234 , 226 , 254 , 175 , 170 , 170 , 170 , 42 , 0 , 186 , 170 , 170 , 170 , 130 , 254 , 255 , 250 , 255 , 255 , 255 , 255 , 255 , 255 , 255 , 46 , 34 , 162 , 34 , 34 , 170 , 170 , 42 , 0 , 0 , 0 , 0 ,
0 , 0 , 0 , 84 , 69 , 85 , 21 , 84 , 85 , 85 , 85 , 68 , 68 , 21 , 84 , 69 , 85 , 87 , 69 , 0 , 64 , 84 , 0 , 80 , 5 , 0 , 64 , 5 , 84 , 85 , 85 , 247 , 255 , 255 , 255 , 255 , 255 , 127 , 85 , 0 , 0 , 0 , 0 , 0 , 85 , 21 , 0 , 0 , 0 , 0 ,
0 , 0 , 0 , 184 , 170 , 170 , 10 , 170 , 170 , 170 , 170 , 170 , 170 , 42 , 168 , 139 , 187 , 191 , 170 , 170 , 170 , 170 , 10 , 168 , 171 , 136 , 136 , 10 , 184 , 171 , 170 , 255 , 255 , 255 , 255 , 255 , 255 , 255 , 171 , 136 , 136 , 8 , 128 , 136 , 170 , 42 , 0 , 0 , 0 , 0 ,
0 , 0 , 0 , 84 , 85 , 85 , 17 , 85 , 81 , 21 , 17 , 0 , 17 , 21 , 80 , 69 , 85 , 85 , 21 , 0 , 0 , 80 , 5 , 0 , 21 , 0 , 0 , 16 , 80 , 17 , 1 , 213 , 221 , 93 , 253 , 255 , 255 , 221 , 85 , 1 , 0 , 0 , 0 , 0 , 16 , 17 , 0 , 0 , 0 , 0 ,
0 , 0 , 0 , 236 , 174 , 170 , 170 , 170 , 170 , 174 , 170 , 170 , 170 , 42 , 234 , 174 , 238 , 254 , 175 , 170 , 170 , 170 , 42 , 160 , 174 , 42 , 34 , 162 , 224 , 171 , 138 , 254 , 255 , 239 , 255 , 255 , 255 , 255 , 255 , 42 , 34 , 34 , 34 , 162 , 170 , 42 , 0 , 0 , 0 , 0 ,
0 , 0 , 0 , 84 , 85 , 85 , 5 , 69 , 68 , 85 , 85 , 68 , 80 , 85 , 84 , 85 , 85 , 85 , 85 , 85 , 0 , 68 , 21 , 64 , 84 , 5 , 0 , 80 , 65 , 85 , 0 , 85 , 85 , 85 , 117 , 255 , 255 , 255 , 255 , 5 , 0 , 0 , 0 , 0 , 80 , 21 , 0 , 0 , 0 , 0 ,
0 , 0 , 0 , 184 , 171 , 170 , 170 , 170 , 168 , 171 , 170 , 170 , 168 , 170 , 168 , 187 , 187 , 170 , 186 , 170 , 170 , 170 , 170 , 128 , 184 , 171 , 170 , 170 , 139 , 171 , 138 , 187 , 171 , 186 , 187 , 255 , 255 , 255 , 255 , 171 , 128 , 8 , 128 , 128 , 168 , 42 , 0 , 0 , 0 , 0 ,
0 , 0 , 0 , 84 , 85 , 85 , 21 , 69 , 64 , 21 , 17 , 16 , 81 , 85 , 81 , 85 , 85 , 0 , 85 , 85 , 1 , 16 , 85 , 1 , 80 , 85 , 85 , 85 , 17 , 21 , 0 , 85 , 85 , 81 , 85 , 85 , 253 , 255 , 223 , 29 , 0 , 0 , 0 , 0 , 0 , 17 , 0 , 0 , 0 , 0 ,
0 , 0 , 0 , 236 , 238 , 170 , 174 , 170 , 232 , 174 , 170 , 170 , 170 , 170 , 234 , 238 , 174 , 170 , 238 , 175 , 170 , 170 , 170 , 2 , 234 , 255 , 255 , 255 , 10 , 174 , 138 , 254 , 174 , 170 , 170 , 234 , 255 , 255 , 255 , 255 , 34 , 34 , 34 , 34 , 170 , 42 , 0 , 0 , 0 , 0 ,
0 , 0 , 0 , 84 , 85 , 85 , 85 , 85 , 64 , 85 , 85 , 68 , 85 , 85 , 85 , 85 , 85 , 0 , 84 , 87 , 69 , 68 , 85 , 5 , 64 , 117 , 117 , 23 , 0 , 84 , 1 , 85 , 85 , 5 , 68 , 85 , 245 , 255 , 255 , 127 , 1 , 0 , 0 , 0 , 0 , 20 , 0 , 0 , 0 , 0 ,
0 , 0 , 0 , 184 , 170 , 170 , 170 , 170 , 160 , 171 , 170 , 170 , 170 , 170 , 186 , 187 , 174 , 138 , 170 , 191 , 170 , 170 , 170 , 10 , 136 , 187 , 187 , 170 , 0 , 184 , 136 , 187 , 170 , 138 , 168 , 170 , 255 , 255 , 255 , 255 , 11 , 0 , 128 , 0 , 136 , 42 , 0 , 0 , 0 , 0 ,
0 , 0 , 0 , 84 , 85 , 85 , 85 , 85 , 81 , 69 , 21 , 80 , 85 , 81 , 85 , 85 , 21 , 0 , 80 , 85 , 21 , 17 , 85 , 21 , 0 , 85 , 17 , 0 , 0 , 16 , 1 , 85 , 85 , 1 , 0 , 64 , 85 , 253 , 255 , 221 , 5 , 0 , 0 , 0 , 0 , 16 , 0 , 0 , 0 , 0 ,
0 , 0 , 0 , 236 , 238 , 234 , 174 , 174 , 226 , 174 , 170 , 170 , 170 , 170 , 234 , 238 , 174 , 42 , 168 , 254 , 171 , 170 , 234 , 42 , 168 , 254 , 170 , 42 , 0 , 160 , 138 , 254 , 174 , 42 , 32 , 234 , 255 , 255 , 255 , 255 , 191 , 34 , 34 , 34 , 34 , 42 , 0 , 0 , 0 , 0 ,
0 , 0 , 0 , 84 , 85 , 85 , 85 , 69 , 81 , 85 , 85 , 64 , 85 , 85 , 85 , 85 , 85 , 4 , 0 , 85 , 85 , 85 , 85 , 85 , 0 , 80 , 69 , 0 , 0 , 64 , 0 , 85 , 85 , 5 , 0 , 64 , 85 , 245 , 255 , 255 , 87 , 0 , 0 , 0 , 0 , 0 , 0 , 0 , 0 , 0 ,
0 , 0 , 0 , 184 , 171 , 170 , 170 , 170 , 170 , 170 , 170 , 168 , 170 , 170 , 170 , 187 , 171 , 10 , 128 , 190 , 191 , 170 , 170 , 170 , 130 , 186 , 170 , 10 , 0 , 160 , 136 , 187 , 171 , 10 , 0 , 160 , 250 , 255 , 255 , 255 , 255 , 10 , 128 , 0 , 0 , 8 , 0 , 0 , 0 , 0 ,
0 , 0 , 0 , 84 , 85 , 85 , 85 , 65 , 81 , 85 , 85 , 80 , 85 , 81 , 85 , 85 , 21 , 1 , 0 , 85 , 85 , 21 , 85 , 85 , 1 , 64 , 16 , 0 , 0 , 64 , 0 , 85 , 85 , 1 , 0 , 0 , 80 , 85 , 253 , 223 , 93 , 1 , 0 , 0 , 0 , 0 , 0 , 0 , 0 , 0 ,
0 , 0 , 0 , 252 , 255 , 175 , 234 , 162 , 234 , 174 , 170 , 168 , 234 , 162 , 234 , 238 , 175 , 42 , 162 , 255 , 255 , 175 , 170 , 170 , 170 , 138 , 170 , 42 , 0 , 224 , 130 , 254 , 174 , 42 , 0 , 0 , 170 , 254 , 255 , 255 , 255 , 47 , 34 , 34 , 34 , 34 , 0 , 0 , 0 , 0 ,
0 , 0 , 0 , 84 , 85 , 85 , 85 , 81 , 81 , 85 , 85 , 81 , 85 , 64 , 85 , 85 , 87 , 84 , 69 , 85 , 85 , 85 , 85 , 85 , 21 , 0 , 65 , 0 , 0 , 64 , 0 , 85 , 85 , 5 , 0 , 0 , 0 , 84 , 85 , 255 , 127 , 71 , 0 , 0 , 0 , 0 , 0 , 0 , 0 , 0 ,
0 , 0 , 0 , 184 , 171 , 171 , 170 , 168 , 170 , 170 , 170 , 168 , 170 , 130 , 170 , 187 , 191 , 170 , 251 , 191 , 187 , 187 , 170 , 170 , 186 , 40 , 170 , 10 , 0 , 128 , 128 , 187 , 170 , 10 , 0 , 0 , 128 , 168 , 250 , 255 , 255 , 191 , 0 , 0 , 0 , 0 , 0 , 0 , 0 , 0 ,
0 , 0 , 0 , 84 , 21 , 85 , 85 , 85 , 81 , 21 , 85 , 81 , 85 , 1 , 85 , 85 , 85 , 85 , 85 , 85 , 85 , 85 , 85 , 85 , 85 , 1 , 4 , 0 , 0 , 0 , 0 , 85 , 85 , 1 , 0 , 0 , 0 , 0 , 80 , 245 , 223 , 93 , 1 , 0 , 0 , 0 , 0 , 0 , 0 , 0 ,
0 , 0 , 0 , 236 , 238 , 254 , 234 , 174 , 234 , 174 , 170 , 234 , 238 , 162 , 234 , 238 , 255 , 239 , 254 , 238 , 239 , 255 , 239 , 170 , 238 , 174 , 170 , 42 , 2 , 128 , 130 , 254 , 174 , 10 , 0 , 0 , 0 , 160 , 170 , 254 , 255 , 255 , 10 , 34 , 34 , 2 , 0 , 0 , 0 , 0 ,
0 , 0 , 0 , 84 , 85 , 85 , 85 , 85 , 85 , 85 , 85 , 85 , 85 , 5 , 69 , 85 , 85 , 85 , 85 , 85 , 85 , 85 , 85 , 85 , 85 , 21 , 0 , 4 , 0 , 0 , 0 , 85 , 85 , 1 , 0 , 0 , 0 , 0 , 68 , 85 , 255 , 127 , 5 , 0 , 0 , 0 , 0 , 0 , 0 , 0 ,
0 , 0 , 0 , 168 , 250 , 191 , 170 , 171 , 186 , 170 , 170 , 170 , 170 , 138 , 170 , 187 , 191 , 187 , 186 , 186 , 250 , 191 , 187 , 170 , 170 , 187 , 168 , 10 , 0 , 128 , 138 , 187 , 170 , 10 , 0 , 0 , 0 , 0 , 160 , 170 , 255 , 255 , 43 , 0 , 0 , 0 , 0 , 0 , 0 , 0 ,
0 , 0 , 0 , 84 , 221 , 85 , 85 , 85 , 85 , 21 , 81 , 85 , 85 , 21 , 0 , 85 , 85 , 85 , 81 , 81 , 213 , 93 , 85 , 85 , 85 , 85 , 1 , 0 , 0 , 0 , 1 , 85 , 85 , 1 , 0 , 0 , 0 , 0 , 0 , 80 , 213 , 255 , 21 , 0 , 0 , 0 , 0 , 0 , 0 , 0 ,
0 , 0 , 0 , 236 , 255 , 255 , 239 , 170 , 234 , 174 , 170 , 238 , 238 , 46 , 170 , 239 , 238 , 238 , 234 , 234 , 254 , 255 , 255 , 239 , 234 , 239 , 170 , 42 , 2 , 128 , 130 , 254 , 238 , 42 , 0 , 0 , 0 , 0 , 0 , 170 , 254 , 255 , 191 , 0 , 34 , 0 , 0 , 0 , 0 , 0 ,
0 , 0 , 0 , 212 , 127 , 85 , 85 , 85 , 85 , 85 , 85 , 85 , 85 , 21 , 0 , 85 , 85 , 85 , 85 , 85 , 119 , 119 , 87 , 85 , 85 , 85 , 5 , 4 , 0 , 0 , 0 , 85 , 85 , 5 , 0 , 0 , 0 , 0 , 0 , 0 , 84 , 245 , 87 , 0 , 0 , 0 , 0 , 0 , 0 , 0 ,
0 , 0 , 0 , 252 , 191 , 168 , 171 , 171 , 170 , 170 , 170 , 170 , 170 , 170 , 136 , 187 , 187 , 187 , 234 , 170 , 255 , 255 , 255 , 191 , 187 , 187 , 43 , 42 , 0 , 128 , 128 , 187 , 170 , 10 , 0 , 0 , 0 , 0 , 0 , 0 , 168 , 250 , 255 , 2 , 0 , 0 , 0 , 0 , 0 , 0 ,
0 , 0 , 0 , 220 , 85 , 80 , 85 , 85 , 85 , 85 , 81 , 85 , 85 , 21 , 0 , 85 , 85 , 85 , 81 , 81 , 213 , 85 , 93 , 85 , 85 , 85 , 21 , 4 , 0 , 0 , 0 , 85 , 85 , 1 , 0 , 0 , 0 , 0 , 0 , 0 , 0 , 85 , 93 , 1 , 0 , 0 , 0 , 0 , 0 , 0 ,
0 , 0 , 0 , 252 , 170 , 224 , 174 , 174 , 234 , 238 , 234 , 238 , 238 , 174 , 170 , 234 , 254 , 238 , 234 , 238 , 238 , 255 , 255 , 239 , 255 , 239 , 254 , 40 , 34 , 160 , 130 , 238 , 238 , 42 , 0 , 0 , 0 , 0 , 0 , 0 , 0 , 234 , 254 , 11 , 0 , 0 , 0 , 0 , 0 , 0 ,
0 , 0 , 0 , 124 , 85 , 64 , 85 , 85 , 85 , 85 , 85 , 85 , 85 , 85 , 4 , 85 , 85 , 85 , 85 , 85 , 85 , 119 , 119 , 85 , 85 , 85 , 85 , 80 , 0 , 0 , 4 , 85 , 85 , 5 , 0 , 0 , 0 , 0 , 0 , 0 , 0 , 64 , 245 , 7 , 0 , 0 , 0 , 0 , 0 , 0 ,
0 , 0 , 0 , 252 , 170 , 160 , 170 , 170 , 170 , 170 , 170 , 170 , 170 , 170 , 138 , 171 , 187 , 187 , 234 , 171 , 171 , 254 , 255 , 191 , 251 , 187 , 187 , 171 , 0 , 128 , 170 , 187 , 170 , 10 , 0 , 0 , 0 , 0 , 0 , 0 , 0 , 128 , 170 , 47 , 0 , 0 , 0 , 0 , 0 , 0 ,
0 , 0 , 0 , 124 , 21 , 80 , 85 , 85 , 17 , 85 , 85 , 85 , 85 , 85 , 21 , 85 , 85 , 85 , 81 , 85 , 85 , 85 , 85 , 85 , 85 , 85 , 85 , 81 , 1 , 0 , 85 , 85 , 85 , 1 , 0 , 0 , 0 , 0 , 0 , 0 , 0 , 0 , 80 , 93 , 0 , 0 , 0 , 0 , 0 , 0 ,
0 , 0 , 0 , 252 , 174 , 226 , 174 , 174 , 170 , 234 , 170 , 238 , 238 , 238 , 174 , 234 , 255 , 255 , 234 , 255 , 239 , 254 , 255 , 255 , 234 , 255 , 255 , 174 , 35 , 160 , 238 , 239 , 238 , 42 , 0 , 0 , 0 , 0 , 0 , 0 , 0 , 0 , 160 , 254 , 0 , 0 , 0 , 0 , 0 , 0 ,
0 , 0 , 0 , 84 , 85 , 64 , 85 , 85 , 85 , 85 , 85 , 85 , 85 , 85 , 69 , 85 , 87 , 85 , 85 , 119 , 85 , 117 , 119 , 85 , 85 , 117 , 85 , 85 , 5 , 0 , 85 , 85 , 85 , 5 , 0 , 0 , 0 , 0 , 0 , 0 , 0 , 0 , 0 , 112 , 0 , 0 , 0 , 0 , 0 , 0 ,
0 , 0 , 0 , 184 , 187 , 168 , 171 , 186 , 170 , 170 , 170 , 170 , 187 , 186 , 171 , 170 , 255 , 191 , 251 , 255 , 171 , 235 , 255 , 171 , 170 , 250 , 191 , 187 , 10 , 128 , 187 , 187 , 170 , 10 , 0 , 0 , 0 , 0 , 0 , 0 , 0 , 0 , 0 , 160 , 0 , 0 , 0 , 0 , 0 , 0 ,
0 , 0 , 0 , 84 , 85 , 81 , 21 , 85 , 17 , 81 , 85 , 85 , 85 , 85 , 85 , 85 , 93 , 85 , 213 , 93 , 85 , 85 , 85 , 85 , 85 , 85 , 85 , 85 , 21 , 0 , 85 , 85 , 85 , 1 , 0 , 0 , 0 , 0 , 0 , 0 , 0 , 0 , 0 , 0 , 0 , 0 , 0 , 0 , 0 , 0 ,
0 , 0 , 0 , 236 , 175 , 226 , 171 , 174 , 170 , 170 , 234 , 170 , 238 , 238 , 238 , 234 , 254 , 239 , 254 , 255 , 239 , 238 , 255 , 239 , 174 , 234 , 255 , 239 , 46 , 130 , 175 , 238 , 238 , 42 , 0 , 0 , 0 , 0 , 0 , 0 , 0 , 0 , 0 , 0 , 0 , 10 , 0 , 0 , 0 , 0 ,
0 , 0 , 0 , 84 , 85 , 85 , 85 , 85 , 85 , 85 , 85 , 85 , 85 , 85 , 85 , 69 , 87 , 85 , 117 , 119 , 85 , 85 , 87 , 85 , 85 , 85 , 117 , 85 , 85 , 64 , 5 , 84 , 85 , 5 , 0 , 0 , 0 , 0 , 0 , 0 , 0 , 0 , 0 , 0 , 0 , 0 , 0 , 0 , 0 , 0 ,
0 , 0 , 0 , 184 , 187 , 250 , 171 , 170 , 170 , 170 , 170 , 170 , 186 , 187 , 187 , 170 , 191 , 171 , 250 , 255 , 191 , 171 , 255 , 191 , 170 , 170 , 251 , 255 , 171 , 136 , 138 , 186 , 171 , 10 , 0 , 0 , 0 , 0 , 0 , 0 , 0 , 0 , 0 , 0 , 0 , 10 , 0 , 0 , 0 , 0 ,
0 , 0 , 0 , 84 , 85 , 85 , 85 , 21 , 81 , 85 , 85 , 85 , 85 , 85 , 85 , 85 , 85 , 85 , 213 , 85 , 85 , 1 , 85 , 85 , 85 , 81 , 85 , 85 , 85 , 1 , 1 , 80 , 85 , 1 , 0 , 0 , 0 , 0 , 0 , 0 , 0 , 0 , 0 , 0 , 0 , 0 , 0 , 0 , 0 , 0 ,
0 , 0 , 0 , 236 , 238 , 238 , 238 , 174 , 170 , 170 , 238 , 238 , 238 , 254 , 255 , 174 , 254 , 238 , 238 , 255 , 239 , 170 , 255 , 239 , 174 , 234 , 238 , 254 , 175 , 226 , 35 , 234 , 239 , 42 , 0 , 0 , 0 , 0 , 0 , 0 , 0 , 0 , 0 , 2 , 0 , 10 , 0 , 0 , 0 , 0 ,
0 , 0 , 0 , 84 , 85 , 85 , 85 , 85 , 85 , 85 , 85 , 85 , 85 , 85 , 85 , 85 , 85 , 85 , 85 , 119 , 87 , 68 , 87 , 85 , 85 , 68 , 85 , 117 , 87 , 101 , 1 , 64 , 85 , 5 , 0 , 0 , 0 , 0 , 0 , 0 , 0 , 0 , 0 , 0 , 0 , 4 , 0 , 0 , 0 , 0 ,
0 , 0 , 0 , 168 , 186 , 187 , 187 , 170 , 170 , 170 , 186 , 187 , 187 , 191 , 187 , 171 , 191 , 187 , 251 , 255 , 191 , 170 , 255 , 187 , 171 , 170 , 170 , 251 , 191 , 234 , 139 , 168 , 170 , 10 , 0 , 0 , 0 , 0 , 0 , 0 , 0 , 0 , 0 , 0 , 128 , 0 , 0 , 0 , 0 , 0 ,
0 , 0 , 0 , 84 , 85 , 85 , 85 , 81 , 17 , 85 , 85 , 85 , 85 , 93 , 93 , 85 , 85 , 85 , 213 , 85 , 21 , 16 , 85 , 85 , 85 , 84 , 85 , 85 , 85 , 69 , 1 , 0 , 85 , 1 , 0 , 0 , 0 , 0 , 0 , 0 , 0 , 0 , 0 , 0 , 0 , 0 , 0 , 0 , 0 , 0 ,
0 , 0 , 0 , 236 , 238 , 254 , 238 , 170 , 170 , 234 , 238 , 238 , 238 , 255 , 255 , 255 , 255 , 174 , 254 , 255 , 174 , 170 , 254 , 239 , 234 , 234 , 238 , 238 , 238 , 251 , 162 , 174 , 238 , 42 , 0 , 0 , 0 , 0 , 0 , 0 , 0 , 0 , 2 , 34 , 34 , 14 , 0 , 0 , 0 , 0 ,
0 , 0 , 0 , 84 , 85 , 85 , 85 , 85 , 85 , 85 , 85 , 85 , 85 , 119 , 119 , 87 , 85 , 85 , 116 , 87 , 85 , 84 , 87 , 85 , 85 , 84 , 85 , 85 , 85 , 113 , 1 , 84 , 85 , 5 , 0 , 0 , 0 , 0 , 0 , 0 , 0 , 0 , 0 , 0 , 0 , 0 , 0 , 0 , 0 , 0 ,
0 , 0 , 0 , 188 , 186 , 187 , 186 , 170 , 170 , 170 , 187 , 187 , 187 , 255 , 255 , 255 , 191 , 43 , 248 , 171 , 174 , 170 , 254 , 171 , 171 , 170 , 170 , 170 , 170 , 250 , 42 , 184 , 186 , 10 , 0 , 0 , 0 , 0 , 0 , 0 , 0 , 0 , 0 , 0 , 0 , 0 , 0 , 0 , 0 , 0 ,
0 , 0 , 0 , 92 , 85 , 85 , 85 , 17 , 85 , 85 , 85 , 85 , 85 , 221 , 221 , 85 , 85 , 1 , 84 , 85 , 21 , 17 , 85 , 85 , 85 , 85 , 85 , 85 , 85 , 89 , 17 , 16 , 85 , 1 , 0 , 0 , 0 , 0 , 0 , 0 , 0 , 0 , 0 , 0 , 0 , 0 , 0 , 0 , 0 , 0 ,
0 , 0 , 0 , 252 , 254 , 254 , 238 , 170 , 238 , 234 , 255 , 255 , 255 , 255 , 255 , 255 , 239 , 42 , 250 , 187 , 175 , 170 , 254 , 238 , 174 , 234 , 238 , 238 , 174 , 254 , 42 , 170 , 234 , 42 , 0 , 0 , 2 , 0 , 0 , 0 , 32 , 34 , 34 , 162 , 2 , 10 , 0 , 0 , 0 , 0 ,
0 , 0 , 0 , 84 , 85 , 85 , 85 , 85 , 85 , 85 , 85 , 85 , 85 , 119 , 119 , 119 , 85 , 0 , 116 , 85 , 85 , 85 , 117 , 85 , 85 , 85 , 85 , 85 , 85 , 116 , 5 , 0 , 85 , 5 , 0 , 0 , 0 , 0 , 0 , 0 , 0 , 0 , 0 , 0 , 0 , 0 , 0 , 0 , 0 , 0 ,
0 , 0 , 0 , 168 , 187 , 187 , 186 , 170 , 170 , 187 , 187 , 187 , 187 , 255 , 255 , 255 , 171 , 136 , 250 , 251 , 191 , 170 , 254 , 170 , 170 , 170 , 170 , 170 , 170 , 250 , 171 , 136 , 170 , 10 , 0 , 0 , 0 , 0 , 0 , 0 , 0 , 0 , 0 , 128 , 0 , 8 , 0 , 0 , 0 , 0 ,
0 , 0 , 0 , 0 , 85 , 85 , 85 , 17 , 85 , 85 , 85 , 85 , 213 , 85 , 85 , 85 , 5 , 0 , 209 , 85 , 85 , 85 , 93 , 85 , 85 , 85 , 85 , 85 , 21 , 92 , 85 , 1 , 85 , 5 , 0 , 0 , 0 , 0 , 0 , 0 , 0 , 0 , 0 , 0 , 0 , 0 , 0 , 0 , 0 , 0 ,
0 , 0 , 0 , 168 , 254 , 238 , 238 , 170 , 238 , 255 , 255 , 238 , 254 , 255 , 238 , 255 , 175 , 162 , 250 , 255 , 175 , 170 , 254 , 238 , 238 , 238 , 238 , 238 , 174 , 254 , 254 , 175 , 234 , 42 , 0 , 0 , 0 , 0 , 0 , 0 , 0 , 34 , 34 , 10 , 2 , 42 , 0 , 0 , 0 , 0 ,
0 , 0 , 0 , 4 , 84 , 85 , 85 , 85 , 85 , 87 , 87 , 85 , 117 , 87 , 85 , 85 , 5 , 64 , 117 , 85 , 85 , 85 , 127 , 85 , 85 , 85 , 85 , 85 , 5 , 127 , 85 , 87 , 85 , 5 , 0 , 0 , 0 , 0 , 0 , 0 , 0 , 0 , 0 , 0 , 0 , 4 , 0 , 0 , 0 , 0 ,
0 , 0 , 0 , 8 , 232 , 187 , 186 , 171 , 254 , 255 , 191 , 170 , 250 , 191 , 187 , 255 , 139 , 168 , 250 , 251 , 175 , 170 , 255 , 170 , 170 , 186 , 170 , 170 , 138 , 255 , 187 , 239 , 187 , 11 , 0 , 0 , 0 , 0 , 0 , 0 , 0 , 136 , 8 , 0 , 8 , 10 , 0 , 0 , 0 , 0 ,
0 , 0 , 0 , 0 , 64 , 85 , 85 , 85 , 221 , 213 , 85 , 85 , 213 , 85 , 85 , 93 , 1 , 80 , 213 , 85 , 85 , 85 , 85 , 85 , 85 , 85 , 85 , 85 , 193 , 93 , 85 , 85 , 85 , 21 , 0 , 0 , 0 , 0 , 0 , 0 , 0 , 0 , 0 , 0 , 0 , 0 , 0 , 0 , 0 , 0 };
/* USER CODE END PFP */

/* USER CODE BEGIN 0 */
inline void LcdCmdEnable()
{
	HAL_GPIO_WritePin(SCS_GPIO_Port, SCS_Pin, GPIO_PIN_SET);
}

inline void LcdCmdDisable()
{
	HAL_GPIO_WritePin(SCS_GPIO_Port, SCS_Pin, GPIO_PIN_RESET);
}

inline void LcdDispEnable()
{
	HAL_GPIO_WritePin(DISP_GPIO_Port, DISP_Pin, GPIO_PIN_SET);
}

inline void LcdDispDisable()
{
	HAL_GPIO_WritePin(DISP_GPIO_Port, DISP_Pin, GPIO_PIN_RESET);
}

void ClearLCD()
{
	LcdCmdEnable();
	HAL_SPI_Transmit(&hspi2, &LCD_CMD_CLEAR, 1, 0);
	HAL_SPI_Transmit(&hspi2, &LCD_CMD_NOP, 1, 0);
	HAL_Delay(1);
	LcdCmdDisable();
}

void OutputBuff()
{
	LcdCmdEnable();
	HAL_SPI_Transmit(&hspi2, &LCD_CMD_UPDATE, 1, HAL_MAX_DELAY);
	for(uint8_t line = 0; line < 240; line++) {
		uint8_t tmp = line + 1;
		HAL_SPI_Transmit(&hspi2, &tmp, 1, 0);
		for(uint8_t row = 0; row < 50; row++) {
			tmp = ~LCD_BUFF[line][row];
  		HAL_SPI_Transmit(&hspi2, &tmp, 1, HAL_MAX_DELAY);
		}
  	HAL_SPI_Transmit(&hspi2, &LCD_CMD_NOP, 1, HAL_MAX_DELAY);
	}
	HAL_SPI_Transmit(&hspi2, &LCD_CMD_NOP, 1, HAL_MAX_DELAY);
	HAL_SPI_Transmit(&hspi2, &LCD_CMD_NOP, 1, HAL_MAX_DELAY);
	HAL_Delay(1);
	LcdCmdDisable();
}

void OutputTest()
{
	LcdCmdEnable();
	uint8_t receiveData[100] = {0};
	HAL_SPI_TransmitReceive(&hspi2, &LCD_CMD_UPDATE, receiveData, 1, HAL_MAX_DELAY);
  uint8_t tmp = 120; // 0b11110000
	uint8_t test_data[50] = {0};
	test_data[0] = 0x40; // 0b01000111
	test_data[1] = 0x41;
	test_data[2] = 0x42;
	test_data[3] = 0x43;
	test_data[4] = 0x44;
	test_data[5] = 0x45;
	test_data[6] = 0x46;
	HAL_SPI_Transmit(&hspi2, &tmp, 1, HAL_MAX_DELAY);
	HAL_SPI_Transmit(&hspi2, test_data, 50, HAL_MAX_DELAY);
	HAL_SPI_Transmit(&hspi2, &LCD_CMD_NOP, 1, HAL_MAX_DELAY);
	HAL_SPI_Transmit(&hspi2, &LCD_CMD_NOP, 1, HAL_MAX_DELAY);
	HAL_Delay(1);
	LcdCmdDisable();
}
/* USER CODE END 0 */

int main(void)
{

  /* MCU Configuration--------------------------------------------------------*/

  /* Reset of all peripherals, Initializes the Flash interface and the Systick. */
  HAL_Init();

  /* Configure the system clock */
  SystemClock_Config();

  /* Initialize all configured peripherals */
  MX_GPIO_Init();
  MX_TIM3_Init();
  MX_USART2_UART_Init();
  MX_SPI2_Init();
  /* USER CODE BEGIN 2 */
	LcdDispEnable();
  HAL_TIM_PWM_Start(&htim3, TIM_CHANNEL_4);
	ClearLCD();
  /* USER CODE END 2 */

  /* Infinite loop */
  while (1)
  {
  	ClearLCD();
		HAL_Delay(1000);
		OutputBuff();
		HAL_Delay(4000);
  }
}

void SystemClock_Config(void)
{
  RCC_OscInitTypeDef RCC_OscInitStruct = {0};
  RCC_ClkInitTypeDef RCC_ClkInitStruct = {0};
  RCC_PeriphCLKInitTypeDef PeriphClkInit = {0};

  /** Initializes the RCC Oscillators according to the specified parameters
  * in the RCC_OscInitTypeDef structure.
  */
  RCC_OscInitStruct.OscillatorType = RCC_OSCILLATORTYPE_HSI;
  RCC_OscInitStruct.HSIState = RCC_HSI_ON;
  RCC_OscInitStruct.HSICalibrationValue = RCC_HSICALIBRATION_DEFAULT;
  RCC_OscInitStruct.PLL.PLLState = RCC_PLL_ON;
  RCC_OscInitStruct.PLL.PLLSource = RCC_PLLSOURCE_HSI;
  RCC_OscInitStruct.PLL.PLLM = 1;
  RCC_OscInitStruct.PLL.PLLN = 10;
  RCC_OscInitStruct.PLL.PLLP = RCC_PLLP_DIV7;
  RCC_OscInitStruct.PLL.PLLQ = RCC_PLLQ_DIV2;
  RCC_OscInitStruct.PLL.PLLR = RCC_PLLR_DIV2;
  if (HAL_RCC_OscConfig(&RCC_OscInitStruct) != HAL_OK)
  {
    Error_Handler();
  }
  /** Initializes the CPU, AHB and APB buses clocks
  */
  RCC_ClkInitStruct.ClockType = RCC_CLOCKTYPE_HCLK|RCC_CLOCKTYPE_SYSCLK
                              |RCC_CLOCKTYPE_PCLK1|RCC_CLOCKTYPE_PCLK2;
  RCC_ClkInitStruct.SYSCLKSource = RCC_SYSCLKSOURCE_PLLCLK;
  RCC_ClkInitStruct.AHBCLKDivider = RCC_SYSCLK_DIV1;
  RCC_ClkInitStruct.APB1CLKDivider = RCC_HCLK_DIV1;
  RCC_ClkInitStruct.APB2CLKDivider = RCC_HCLK_DIV1;

  if (HAL_RCC_ClockConfig(&RCC_ClkInitStruct, FLASH_LATENCY_4) != HAL_OK)
  {
    Error_Handler();
  }
  PeriphClkInit.PeriphClockSelection = RCC_PERIPHCLK_USART2;
  PeriphClkInit.Usart2ClockSelection = RCC_USART2CLKSOURCE_PCLK1;
  if (HAL_RCCEx_PeriphCLKConfig(&PeriphClkInit) != HAL_OK)
  {
    Error_Handler();
  }
  /** Configure the main internal regulator output voltage
  */
  if (HAL_PWREx_ControlVoltageScaling(PWR_REGULATOR_VOLTAGE_SCALE1) != HAL_OK)
  {
    Error_Handler();
  }
}

static void MX_SPI2_Init(void)
{

  /* SPI2 parameter configuration*/
  hspi2.Instance = SPI2;
  hspi2.Init.Mode = SPI_MODE_MASTER;
  hspi2.Init.Direction = SPI_DIRECTION_2LINES;
  hspi2.Init.DataSize = SPI_DATASIZE_8BIT;
  hspi2.Init.CLKPolarity = SPI_POLARITY_LOW;
  hspi2.Init.CLKPhase = SPI_PHASE_1EDGE;
  hspi2.Init.NSS = SPI_NSS_SOFT;
  hspi2.Init.BaudRatePrescaler = SPI_BAUDRATEPRESCALER_8;
  hspi2.Init.FirstBit = SPI_FIRSTBIT_LSB;
  hspi2.Init.TIMode = SPI_TIMODE_DISABLE;
  hspi2.Init.CRCCalculation = SPI_CRCCALCULATION_DISABLE;
  hspi2.Init.CRCPolynomial = 7;
  hspi2.Init.CRCLength = SPI_CRC_LENGTH_DATASIZE;
  hspi2.Init.NSSPMode = SPI_NSS_PULSE_DISABLE;
  if (HAL_SPI_Init(&hspi2) != HAL_OK)
  {
    Error_Handler();
  }

}

static void MX_TIM3_Init(void)
{

  TIM_ClockConfigTypeDef sClockSourceConfig = {0};
  TIM_MasterConfigTypeDef sMasterConfig = {0};
  TIM_OC_InitTypeDef sConfigOC = {0};

  htim3.Instance = TIM3;
  htim3.Init.Prescaler = 9999;
  htim3.Init.CounterMode = TIM_COUNTERMODE_UP;
  htim3.Init.Period = 199;
  htim3.Init.ClockDivision = TIM_CLOCKDIVISION_DIV1;
  htim3.Init.AutoReloadPreload = TIM_AUTORELOAD_PRELOAD_DISABLE;
  if (HAL_TIM_Base_Init(&htim3) != HAL_OK)
  {
    Error_Handler();
  }
  sClockSourceConfig.ClockSource = TIM_CLOCKSOURCE_INTERNAL;
  if (HAL_TIM_ConfigClockSource(&htim3, &sClockSourceConfig) != HAL_OK)
  {
    Error_Handler();
  }
  if (HAL_TIM_PWM_Init(&htim3) != HAL_OK)
  {
    Error_Handler();
  }
  sMasterConfig.MasterOutputTrigger = TIM_TRGO_RESET;
  sMasterConfig.MasterSlaveMode = TIM_MASTERSLAVEMODE_DISABLE;
  if (HAL_TIMEx_MasterConfigSynchronization(&htim3, &sMasterConfig) != HAL_OK)
  {
    Error_Handler();
  }
  sConfigOC.OCMode = TIM_OCMODE_PWM1;
  sConfigOC.Pulse = 100;
  sConfigOC.OCPolarity = TIM_OCPOLARITY_HIGH;
  sConfigOC.OCFastMode = TIM_OCFAST_DISABLE;
  if (HAL_TIM_PWM_ConfigChannel(&htim3, &sConfigOC, TIM_CHANNEL_4) != HAL_OK)
  {
    Error_Handler();
  }
  HAL_TIM_MspPostInit(&htim3);

}

static void MX_USART2_UART_Init(void)
{

  huart2.Instance = USART2;
  huart2.Init.BaudRate = 115200;
  huart2.Init.WordLength = UART_WORDLENGTH_8B;
  huart2.Init.StopBits = UART_STOPBITS_1;
  huart2.Init.Parity = UART_PARITY_NONE;
  huart2.Init.Mode = UART_MODE_TX_RX;
  huart2.Init.HwFlowCtl = UART_HWCONTROL_NONE;
  huart2.Init.OverSampling = UART_OVERSAMPLING_16;
  huart2.Init.OneBitSampling = UART_ONE_BIT_SAMPLE_DISABLE;
  huart2.AdvancedInit.AdvFeatureInit = UART_ADVFEATURE_NO_INIT;
  if (HAL_UART_Init(&huart2) != HAL_OK)
  {
    Error_Handler();
  }

}

static void MX_GPIO_Init(void)
{
  GPIO_InitTypeDef GPIO_InitStruct = {0};

  /* GPIO Ports Clock Enable */
  __HAL_RCC_GPIOC_CLK_ENABLE();
  __HAL_RCC_GPIOH_CLK_ENABLE();
  __HAL_RCC_GPIOA_CLK_ENABLE();
  __HAL_RCC_GPIOB_CLK_ENABLE();

  /*Configure GPIO pin Output Level */
  HAL_GPIO_WritePin(GPIOB, DISP_Pin|SCS_Pin, GPIO_PIN_RESET);

  /*Configure GPIO pins : DISP_Pin SCS_Pin */
  GPIO_InitStruct.Pin = DISP_Pin|SCS_Pin;
  GPIO_InitStruct.Mode = GPIO_MODE_OUTPUT_PP;
  GPIO_InitStruct.Pull = GPIO_NOPULL;
  GPIO_InitStruct.Speed = GPIO_SPEED_FREQ_LOW;
  HAL_GPIO_Init(GPIOB, &GPIO_InitStruct);

}

void Error_Handler(void)
{
}

/************************ (C) COPYRIGHT STMicroelectronics *****END OF FILE****/
